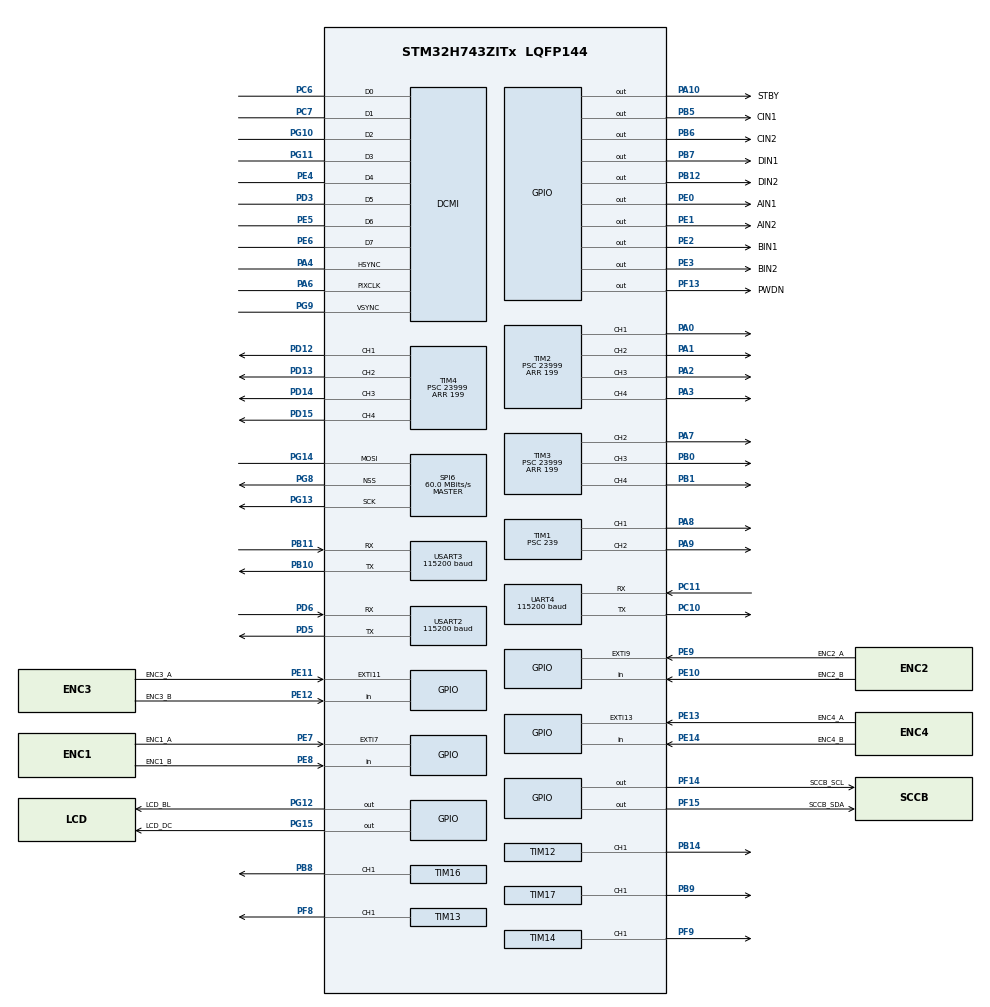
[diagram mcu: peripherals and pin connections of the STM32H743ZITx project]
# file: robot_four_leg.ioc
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CORTEX_M7.AccessPermission-Cortex_Memory_Protection_Unit_Region0_Settings=MPU_REGION_FULL_ACCESS
CORTEX_M7.BaseAddress-Cortex_Memory_Protection_Unit_Region0_Settings=0x30000000
CORTEX_M7.CPU_DCache=Enabled
CORTEX_M7.CPU_ICache=Enabled
CORTEX_M7.Enable-Cortex_Memory_Protection_Unit_Region0_Settings=MPU_REGION_ENABLE
CORTEX_M7.IsBufferable-Cortex_Memory_Protection_Unit_Region0_Settings=MPU_ACCESS_BUFFERABLE
CORTEX_M7.IsCacheable-Cortex_Memory_Protection_Unit_Region0_Settings=MPU_ACCESS_CACHEABLE
CORTEX_M7.IsShareable-Cortex_Memory_Protection_Unit_Region0_Settings=MPU_ACCESS_SHAREABLE
CORTEX_M7.MPU_Control=MPU_PRIVILEGED_DEFAULT
CORTEX_M7.Size-Cortex_Memory_Protection_Unit_Region0_Settings=MPU_REGION_SIZE_512KB
CORTEX_M7.SubRegionDisable-Cortex_Memory_Protection_Unit_Region0_Settings=0x00
CORTEX_M7.default_mode_Activation=0
DCMI.JPEGMode=DCMI_JPEG_DISABLE
DCMI.PCKPolarity=DCMI_PCKPOLARITY_RISING
Dma.DCMI.0.Direction=DMA_PERIPH_TO_MEMORY
Dma.DCMI.0.EventEnable=DISABLE
Dma.DCMI.0.FIFOMode=DMA_FIFOMODE_ENABLE
Dma.DCMI.0.FIFOThreshold=DMA_FIFO_THRESHOLD_HALFFULL
Dma.DCMI.0.Instance=DMA2_Stream7
Dma.DCMI.0.MemBurst=DMA_MBURST_SINGLE
Dma.DCMI.0.MemDataAlignment=DMA_MDATAALIGN_WORD
Dma.DCMI.0.MemInc=DMA_MINC_ENABLE
Dma.DCMI.0.Mode=DMA_CIRCULAR
Dma.DCMI.0.PeriphBurst=DMA_PBURST_SINGLE
Dma.DCMI.0.PeriphDataAlignment=DMA_PDATAALIGN_WORD
Dma.DCMI.0.PeriphInc=DMA_PINC_DISABLE
Dma.DCMI.0.Polarity=HAL_DMAMUX_REQ_GEN_RISING
Dma.DCMI.0.Priority=DMA_PRIORITY_HIGH
Dma.DCMI.0.RequestNumber=1
Dma.DCMI.0.SignalID=NONE
Dma.DCMI.0.SyncEnable=DISABLE
Dma.DCMI.0.SyncPolarity=HAL_DMAMUX_SYNC_NO_EVENT
Dma.DCMI.0.SyncRequestNumber=1
Dma.DCMI.0.SyncSignalID=NONE
Dma.Request0=DCMI
Dma.Request1=USART3_TX
Dma.USART3_TX.1.Direction=DMA_MEMORY_TO_PERIPH
Dma.USART3_TX.1.EventEnable=DISABLE
Dma.USART3_TX.1.FIFOMode=DMA_FIFOMODE_DISABLE
Dma.USART3_TX.1.Instance=DMA1_Stream1
Dma.USART3_TX.1.MemDataAlignment=DMA_MDATAALIGN_BYTE
Dma.USART3_TX.1.MemInc=DMA_MINC_ENABLE
Dma.USART3_TX.1.Mode=DMA_NORMAL
Dma.USART3_TX.1.PeriphDataAlignment=DMA_PDATAALIGN_BYTE
Dma.USART3_TX.1.PeriphInc=DMA_PINC_DISABLE
Dma.USART3_TX.1.Polarity=HAL_DMAMUX_REQ_GEN_RISING
Dma.USART3_TX.1.Priority=DMA_PRIORITY_LOW
Dma.USART3_TX.1.RequestNumber=1
Dma.USART3_TX.1.SignalID=NONE
Dma.USART3_TX.1.SyncEnable=DISABLE
Dma.USART3_TX.1.SyncPolarity=HAL_DMAMUX_SYNC_NO_EVENT
Dma.USART3_TX.1.SyncRequestNumber=1
Dma.USART3_TX.1.SyncSignalID=NONE
IWDG1.Prescaler=IWDG_PRESCALER_32
IWDG1.Reload=2047
Mcu.Family=STM32H7
Mcu.Name=STM32H743ZITx
Mcu.Package=LQFP144
NVIC.DCMI_IRQn=true\:0\:0\:false\:false\:true\:true\:true\:true
NVIC.DMA1_Stream1_IRQn=true\:0\:0\:false\:false\:true\:false\:true\:true
NVIC.DMA2_Stream7_IRQn=true\:0\:0\:false\:false\:true\:false\:true\:true
NVIC.EXTI15_10_IRQn=true\:0\:0\:false\:false\:true\:true\:true\:true
NVIC.EXTI9_5_IRQn=true\:6\:0\:true\:false\:true\:true\:true\:true
NVIC.PriorityGroup=NVIC_PRIORITYGROUP_4
NVIC.TIM6_DAC_IRQn=true\:15\:0\:false\:false\:true\:false\:true\:true
NVIC.TimeBase=TIM6_DAC_IRQn
NVIC.TimeBaseIP=TIM6
NVIC.UART4_IRQn=true\:0\:0\:false\:false\:true\:true\:true\:true
NVIC.USART2_IRQn=true\:5\:0\:true\:false\:true\:true\:true\:true
NVIC.USART3_IRQn=true\:5\:0\:true\:false\:true\:true\:true\:true
PA0.Signal=S_TIM2_CH1_ETR
PA1.Signal=S_TIM2_CH2
PA10.GPIO_Label=STBY
PA10.Signal=GPIO_Output
PA2.Signal=S_TIM2_CH3
PA3.Signal=S_TIM2_CH4
PA4.GPIO_PuPd=GPIO_PULLUP
PA4.GPIO_Speed=GPIO_SPEED_FREQ_VERY_HIGH
PA4.Mode=Slave_8_bits_External_Synchro
PA4.Signal=DCMI_HSYNC
PA6.GPIO_PuPd=GPIO_PULLUP
PA6.GPIO_Speed=GPIO_SPEED_FREQ_VERY_HIGH
PA6.Mode=Slave_8_bits_External_Synchro
PA6.Signal=DCMI_PIXCLK
PA7.Signal=S_TIM3_CH2
PA8.Signal=S_TIM1_CH1
PA9.Signal=S_TIM1_CH2
PB0.Signal=S_TIM3_CH3
PB1.Signal=S_TIM3_CH4
PB10.Mode=Asynchronous
PB10.Signal=USART3_TX
PB11.Mode=Asynchronous
PB11.Signal=USART3_RX
PB12.GPIO_Label=DIN2
PB12.Signal=GPIO_Output
PB14.Signal=S_TIM12_CH1
PB5.GPIO_Label=CIN1
PB5.Signal=GPIO_Output
PB6.GPIO_Label=CIN2
PB6.Signal=GPIO_Output
PB7.GPIO_Label=DIN1
PB7.Signal=GPIO_Output
PB8.Signal=S_TIM16_CH1
PB9.Signal=S_TIM17_CH1
PC10.Mode=Asynchronous
PC10.Signal=UART4_TX
PC11.Mode=Asynchronous
PC11.Signal=UART4_RX
PC14-OSC32_IN\ (OSC32_IN).Mode=LSE-External-Oscillator
PC14-OSC32_IN\ (OSC32_IN).Signal=RCC_OSC32_IN
PC15-OSC32_OUT\ (OSC32_OUT).Mode=LSE-External-Oscillator
PC15-OSC32_OUT\ (OSC32_OUT).Signal=RCC_OSC32_OUT
PC6.GPIO_PuPd=GPIO_PULLUP
PC6.GPIO_Speed=GPIO_SPEED_FREQ_VERY_HIGH
PC6.Mode=Slave_8_bits_External_Synchro
PC6.Signal=DCMI_D0
PC7.GPIO_PuPd=GPIO_PULLUP
PC7.GPIO_Speed=GPIO_SPEED_FREQ_VERY_HIGH
PC7.Mode=Slave_8_bits_External_Synchro
PC7.Signal=DCMI_D1
PD12.Signal=S_TIM4_CH1
PD13.Signal=S_TIM4_CH2
PD14.Signal=S_TIM4_CH3
PD15.Signal=S_TIM4_CH4
PD3.GPIO_PuPd=GPIO_PULLUP
PD3.GPIO_Speed=GPIO_SPEED_FREQ_VERY_HIGH
PD3.Mode=Slave_8_bits_External_Synchro
PD3.Signal=DCMI_D5
PD5.Mode=Asynchronous
PD5.Signal=USART2_TX
PD6.Mode=Asynchronous
PD6.Signal=USART2_RX
PE0.GPIO_Label=AIN1
PE0.Signal=GPIO_Output
PE1.GPIO_Label=AIN2
PE1.Signal=GPIO_Output
PE10.GPIO_Label=ENC2_B
PE10.GPIO_PuPd=GPIO_PULLUP
PE10.Signal=GPIO_Input
PE11.GPIO_Label=ENC3_A
PE11.GPIO_ModeDefaultEXTI=GPIO_MODE_IT_RISING_FALLING
PE11.GPIO_PuPd=GPIO_PULLUP
PE11.Signal=GPXTI11
PE12.GPIO_Label=ENC3_B
PE12.GPIO_PuPd=GPIO_PULLUP
PE12.Signal=GPIO_Input
PE13.GPIO_Label=ENC4_A
PE13.GPIO_ModeDefaultEXTI=GPIO_MODE_IT_RISING_FALLING
PE13.GPIO_PuPd=GPIO_PULLUP
PE13.Signal=GPXTI13
PE14.GPIO_Label=ENC4_B
PE14.GPIO_PuPd=GPIO_PULLUP
PE14.Signal=GPIO_Input
PE2.GPIO_Label=BIN1
PE2.Signal=GPIO_Output
PE3.GPIO_Label=BIN2
PE3.Signal=GPIO_Output
PE4.GPIO_PuPd=GPIO_PULLUP
PE4.GPIO_Speed=GPIO_SPEED_FREQ_VERY_HIGH
PE4.Mode=Slave_8_bits_External_Synchro
PE4.Signal=DCMI_D4
PE5.GPIO_PuPd=GPIO_PULLUP
PE5.GPIO_Speed=GPIO_SPEED_FREQ_VERY_HIGH
PE5.Mode=Slave_8_bits_External_Synchro
PE5.Signal=DCMI_D6
PE6.GPIO_PuPd=GPIO_PULLUP
PE6.GPIO_Speed=GPIO_SPEED_FREQ_VERY_HIGH
PE6.Mode=Slave_8_bits_External_Synchro
PE6.Signal=DCMI_D7
PE7.GPIO_Label=ENC1_A
PE7.GPIO_ModeDefaultEXTI=GPIO_MODE_IT_RISING_FALLING
PE7.GPIO_PuPd=GPIO_PULLUP
PE7.Signal=GPXTI7
PE8.GPIO_Label=ENC1_B
PE8.GPIO_PuPd=GPIO_PULLUP
PE8.Signal=GPIO_Input
PE9.GPIO_Label=ENC2_A
PE9.GPIO_ModeDefaultEXTI=GPIO_MODE_IT_RISING_FALLING
PE9.GPIO_PuPd=GPIO_PULLUP
PE9.Signal=GPXTI9
PF13.GPIO_Label=PWDN
PF13.GPIO_PuPd=GPIO_PULLUP
PF13.Signal=GPIO_Output
PF14.GPIO_Label=SCCB_SCL
PF14.GPIO_ModeDefaultOutputPP=GPIO_MODE_OUTPUT_OD
PF14.GPIO_PuPd=GPIO_NOPULL
PF14.PinState=GPIO_PIN_SET
PF14.Signal=GPIO_Output
PF15.GPIO_Label=SCCB_SDA
PF15.GPIO_ModeDefaultOutputPP=GPIO_MODE_OUTPUT_OD
PF15.GPIO_PuPd=GPIO_NOPULL
PF15.PinState=GPIO_PIN_SET
PF15.Signal=GPIO_Output
PF8.Signal=S_TIM13_CH1
PF9.Signal=S_TIM14_CH1
PG10.GPIO_PuPd=GPIO_PULLUP
PG10.Mode=Slave_8_bits_External_Synchro
PG10.Signal=DCMI_D2
PG11.GPIO_PuPd=GPIO_PULLUP
PG11.Mode=Slave_8_bits_External_Synchro
PG11.Signal=DCMI_D3
PG12.GPIO_Label=LCD_BL
PG12.Signal=GPIO_Output
PG13.GPIO_Speed=GPIO_SPEED_FREQ_VERY_HIGH
PG13.Mode=Simplex_Bidirectional_Master
PG13.Signal=SPI6_SCK
PG14.GPIO_Speed=GPIO_SPEED_FREQ_VERY_HIGH
PG14.Mode=Simplex_Bidirectional_Master
PG14.Signal=SPI6_MOSI
PG15.GPIO_Label=LCD_DC
PG15.Signal=GPIO_Output
PG8.GPIO_Speed=GPIO_SPEED_FREQ_VERY_HIGH
PG8.Mode=NSS_Signal_Hard_Output
PG8.Signal=SPI6_NSS
PG9.GPIO_PuPd=GPIO_PULLUP
PG9.GPIO_Speed=GPIO_SPEED_FREQ_VERY_HIGH
PG9.Mode=Slave_8_bits_External_Synchro
PG9.Signal=DCMI_VSYNC
PH0-OSC_IN\ (PH0).Mode=HSE-External-Oscillator
PH0-OSC_IN\ (PH0).Signal=RCC_OSC_IN
PH1-OSC_OUT\ (PH1).Mode=HSE-External-Oscillator
PH1-OSC_OUT\ (PH1).Signal=RCC_OSC_OUT
ProjectManager.HeapSize=0x200
ProjectManager.StackSize=0x400
ProjectManager.TargetToolchain=STM32CubeIDE
RCC.ADCFreq_Value=129000000
RCC.APB1Freq_Value=120000000
RCC.APB2Freq_Value=120000000
RCC.APB3Freq_Value=120000000
RCC.APB4Freq_Value=120000000
RCC.CortexFreq_Value=480000000
RCC.D1PPRE=RCC_APB3_DIV2
RCC.D2PPRE1=RCC_APB1_DIV2
RCC.D2PPRE2=RCC_APB2_DIV2
RCC.D3PPRE=RCC_APB4_DIV2
RCC.DIVM1=4
RCC.DIVN1=60
RCC.HCLKFreq_Value=240000000
RCC.HPRE=RCC_HCLK_DIV2
RCC.PLL2FRACN=0
RCC.PLL3FRACN=0
RCC.PLLFRACN=0
RCC.SYSCLKFreq_VALUE=480000000
RCC.SYSCLKSource=RCC_SYSCLKSOURCE_PLLCLK
RCC.USBFreq_Value=480000000
SH.S_TIM12_CH1.0=TIM12_CH1,PWM Generation1 CH1
SH.S_TIM13_CH1.0=TIM13_CH1,PWM Generation1 CH1
SH.S_TIM14_CH1.0=TIM14_CH1,PWM Generation1 CH1
SH.S_TIM16_CH1.0=TIM16_CH1,PWM Generation1 CH1
SH.S_TIM17_CH1.0=TIM17_CH1,PWM Generation1 CH1
SH.S_TIM1_CH1.0=TIM1_CH1,PWM Generation1 CH1
SH.S_TIM1_CH2.0=TIM1_CH2,PWM Generation2 CH2
SH.S_TIM2_CH1_ETR.0=TIM2_CH1,PWM Generation1 CH1
SH.S_TIM2_CH2.0=TIM2_CH2,PWM Generation2 CH2
SH.S_TIM2_CH3.0=TIM2_CH3,PWM Generation3 CH3
SH.S_TIM2_CH4.0=TIM2_CH4,PWM Generation4 CH4
SH.S_TIM3_CH2.0=TIM3_CH2,PWM Generation2 CH2
SH.S_TIM3_CH3.0=TIM3_CH3,PWM Generation3 CH3
SH.S_TIM3_CH4.0=TIM3_CH4,PWM Generation4 CH4
SH.S_TIM4_CH1.0=TIM4_CH1,PWM Generation1 CH1
SH.S_TIM4_CH2.0=TIM4_CH2,PWM Generation2 CH2
SH.S_TIM4_CH3.0=TIM4_CH3,PWM Generation3 CH3
SH.S_TIM4_CH4.0=TIM4_CH4,PWM Generation4 CH4
SPI6.CalculateBaudRate=60.0 MBits/s
SPI6.DataSize=SPI_DATASIZE_8BIT
SPI6.Direction=SPI_DIRECTION_1LINE
SPI6.FifoThreshold=SPI_FIFO_THRESHOLD_02DATA
SPI6.Mode=SPI_MODE_MASTER
SPI6.VirtualNSS=VM_NSSHARD
SPI6.VirtualType=VM_MASTER
TIM1.Channel-PWM\ Generation1\ CH1=TIM_CHANNEL_1
TIM1.Channel-PWM\ Generation2\ CH2=TIM_CHANNEL_2
TIM1.Period=99
TIM1.Prescaler=239
TIM12.AutoReloadPreload=TIM_AUTORELOAD_PRELOAD_ENABLE
TIM12.Channel-PWM\ Generation1\ CH1=TIM_CHANNEL_1
TIM12.Period=199
TIM12.Prescaler=23999
TIM13.AutoReloadPreload=TIM_AUTORELOAD_PRELOAD_ENABLE
TIM13.Channel=TIM_CHANNEL_1
TIM13.Period=199
TIM13.Prescaler=23999
TIM14.AutoReloadPreload=TIM_AUTORELOAD_PRELOAD_ENABLE
TIM14.Channel=TIM_CHANNEL_1
TIM14.Period=199
TIM14.Prescaler=23999
TIM16.Channel=TIM_CHANNEL_1
TIM16.Period=99
TIM16.Prescaler=239
TIM17.Channel=TIM_CHANNEL_1
TIM17.Period=99
TIM17.Prescaler=239
TIM2.AutoReloadPreload=TIM_AUTORELOAD_PRELOAD_ENABLE
TIM2.Channel-PWM\ Generation1\ CH1=TIM_CHANNEL_1
TIM2.Channel-PWM\ Generation2\ CH2=TIM_CHANNEL_2
TIM2.Channel-PWM\ Generation3\ CH3=TIM_CHANNEL_3
TIM2.Channel-PWM\ Generation4\ CH4=TIM_CHANNEL_4
TIM2.Period=199
TIM2.Prescaler=23999
TIM3.AutoReloadPreload=TIM_AUTORELOAD_PRELOAD_ENABLE
TIM3.Channel-PWM\ Generation2\ CH2=TIM_CHANNEL_2
TIM3.Channel-PWM\ Generation3\ CH3=TIM_CHANNEL_3
TIM3.Channel-PWM\ Generation4\ CH4=TIM_CHANNEL_4
TIM3.Period=199
TIM3.Prescaler=23999
TIM4.AutoReloadPreload=TIM_AUTORELOAD_PRELOAD_ENABLE
TIM4.Channel-PWM\ Generation1\ CH1=TIM_CHANNEL_1
TIM4.Channel-PWM\ Generation2\ CH2=TIM_CHANNEL_2
TIM4.Channel-PWM\ Generation3\ CH3=TIM_CHANNEL_3
TIM4.Channel-PWM\ Generation4\ CH4=TIM_CHANNEL_4
TIM4.Period=199
TIM4.Prescaler=23999
UART4.BaudRate=115200
USART2.BaudRate=115200
USART2.VirtualMode-Asynchronous=VM_ASYNC
USART3.BaudRate=115200
USART3.VirtualMode-Asynchronous=VM_ASYNC
VP_IWDG1_VS_IWDG.Mode=IWDG_Activate
VP_MEMORYMAP_VS_MEMORYMAP.Mode=CurAppReg
VP_SYS_VS_tim6.Mode=TIM6
VP_TIM12_VS_ClockSourceINT.Mode=Internal
VP_TIM13_VS_ClockSourceINT.Mode=Enable_Timer
VP_TIM14_VS_ClockSourceINT.Mode=Enable_Timer
VP_TIM16_VS_ClockSourceINT.Mode=Enable_Timer
VP_TIM17_VS_ClockSourceINT.Mode=Enable_Timer
VP_TIM1_VS_ClockSourceINT.Mode=Internal
VP_TIM5_VS_ClockSourceINT.Mode=Internal
board=custom

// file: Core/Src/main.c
/* USER CODE BEGIN Header */
/**
  ******************************************************************************
  * @file           : main.c
  * @brief          : Main program body
  ******************************************************************************
  * @attention
  *
  * Copyright (c) 2026 STMicroelectronics.
  * All rights reserved.
  *
  * This software is licensed under terms that can be found in the LICENSE file
  * in the root directory of this software component.
  * If no LICENSE file comes with this software, it is provided AS-IS.
  *
  ******************************************************************************
  */
/* USER CODE END Header */
#include "main.h"
#include "dcmi.h"
#include "dma.h"
#include "iwdg.h"
#include "spi.h"
#include "tim.h"
#include "usart.h"
#include "gpio.h"

/* USER CODE BEGIN Includes */
#include "motor_control.h"
#include "new_servo.h"
#include "leg_control.h"
#include "encoder.h"
#include "bluetooth_control.h"
#include "imu.h"
#include "leg_ik.h"
#include "walk_gait.h"
#include "attitude_control.h"
#include "drive_ctrl.h"
#include "gimbal.h"
#include <stdio.h>
#include <math.h>
/* USER CODE END Includes */

/* USER CODE BEGIN PTD */
/* 控制模式: 上电默认校准模式(不动), 蓝牙命令切换 */
typedef enum { MODE_CALIB = 0, MODE_STAND, MODE_TROT, MODE_STEP } ctrl_mode_t;

#define CROUCH_X_F   30.0f    /* 正常分支低趴: 前腿足端前伸 (膝轴离地86mm) */
#define CROUCH_X_FR 114.5f    /* 反折分支低趴: 前足+129.5, 大腿≈水平(q2=85)+小腿垂直(q3=-85) */
#define CROUCH_X_R  144.5f    /* 正常分支低趴后伸: 后足15-144.5=-129.5, 与前足对称 (L 视觉姿态) */
#define CROUCH_X_RR 135.0f    /* 反折分支低趴后伸 (支撑中心在身下, 前后对称) */

#define FLIP_H         240.0f /* 翻膝机动高度: 此高度下前膝全程≥110mm */
#define FLIP_SEG_MS    900u   /* 翻膝单段时长 (伸/收各900ms) */
#define FLIP_SETTLE_MS 800u   /* 到位后等待平滑收敛再翻膝 */

#define PARK_H          72.0f /* 收纳姿态站高: 贴地趴 (肚皮离地~32mm, 断电无砸落) */
#define PARK_X_F       282.0f /* 贴地趴前足前伸量 (15+282=297, 腿伸直) */
#define PARK_X_R       312.0f /* 贴地趴后足后伸量 (15-312=-297) */

#define RISE_CM_X       15.0f /* 站起阶段重心后移量: 足端前移=身体后坐, 卸载前腿 */
#define RISE_CM_Y       10.0f /* 站起阶段重心左移量: 卸载右腿(FR堵转), 载荷给强壮的RL */

#define SIT_Z_F        310.0f /* 坐姿前腿足端z: 腿竖直伸直 (q2≈q3≈0, 直腿点) */
#define SIT_Z_R        240.0f /* 坐姿后腿足端z: 反折深蹲 */
#define SIT_X_R         95.0f /* 坐姿后足后伸量 (15-95=-80, 膝后折72°) */

/* 前后腿膝分支: 0=正常(狗姿态) 1=反折(膝盖往前顶) */
static uint8_t  g_front_rev = 0;
static uint8_t  g_rear_rev  = 0;
static uint8_t  g_park      = 0;   /* 收纳姿态 (C 命令): 72mm 贴地趴 */
static uint8_t  g_sit       = 0;   /* 坐姿 (O 命令): 前腿竖直伸直 + 后腿反折深蹲 */
static uint8_t  g_rise      = 0;   /* 规划式站起 (U 命令): 1=阶段A收腿+顶升 */
static uint32_t g_rise_t0   = 0;
static float    g_rise_h0   = 0;   /* 站起阶段A起始高度 */
static uint8_t  g_booted    = 1;   /* 刚上电标志: U 站起在上电后可用 (假定在趴姿) */

/* 控制模式与行走时刻 (PTD 函数也要用, 声明放这里) */
static ctrl_mode_t g_mode    = MODE_CALIB;
static uint32_t    g_walk_t0 = 0; /* 行走起始时刻 (相位基准) */

/* 横移走状态: F 命令开启 (0=前后trot, 1=横向螃蟹步), g_lat_dir 为方向 */
static uint8_t  g_gait_lat = 0;
static int      g_lat_dir  = 1;

/* 自稳标定: Z 命令采样中标志 (完成时发 CAL:OK) */
static uint8_t  g_calib_pending = 0;

/* 站立自稳: L:1/L:0 开关, 10Hz 更新四腿z补偿 (仅H/K高站姿, Z标定后可用) */
static float    g_lv_dz[4] = {0, 0, 0, 0};
static uint32_t g_lv_last  = 0;
static uint8_t  g_lv_act   = 0;   /* 自稳激活状态 (10Hz块更新, 行走循环消费) */

/* W原地抬腿重心左移补偿 (mm): 机身右侧偏重 → 右倾+右转, 足端右移=身体左移
 * W:毫米 命令在线调 (默认15) */
static float    g_w_com = 15.0f;

/* 按键页速度档 (D 命令缺省速度, U:1/U:0 加减, 步进5, 范围10~50) */
static int8_t   g_btn_spd     = 30;
static uint8_t  g_btn_dir     = 0;    /* 最后按键方向 */
static uint8_t  g_btn_mode    = 0;    /* 最后按键模式 0=经典 1=无倾斜页 */
static uint8_t  g_btn_driving = 0;    /* 当前是否按键驾驶中 (V摇杆接管时清) */

/* 站姿宽度偏移 (Y:毫米 命令, ±40, 默认0): 每足足端向外偏移, 支撑面加宽
 * 崎岖地面抗侧倾测试用; 同时用于实测验证外展y通道方向 */
static float    g_stance_w = 0.0f;

/* 单腿抬腿 (N:腿:动作): 任意时刻只操作一条腿
 * 抬起 50mm + 前伸 80mm (实测确认), 放下后足端停在前伸位, 姿态命令收回 */
#define LEGLIFT_H      50.0f   /* 抬腿高度 mm */
#define LEGLIFT_FWD    80.0f   /* 前伸量 mm */
#define LEGLIFT_UP_MS  800u    /* 抬起耗时 */
#define LEGLIFT_DN_MS  1200u   /* 放下耗时 (慢慢放) */
#define LEGLIFT_SHIFT  15.0f   /* 支撑腿重心横移 (mm): 远离抬起腿, 重心移进支撑三角形 */
#define LEGLIFT_STAG_MS 0u     /* 双腿模式交错间隔 (2026-08-25 改同时抬: 0=同时) */
static uint8_t  g_lift_leg   = 0xFF; /* 当前抬起的腿 0~3, 0xFF=无 */
static uint8_t  g_lift_phase = 0;    /* 1=抬起中 2=悬空 3=放下中 (0=待命) */
static uint32_t g_lift_t0    = 0;
static float    g_lift_x0    = 0;    /* 抬起起始x (站立位+前伸记忆) */
static float    g_lift_z3    = 0;    /* 放下起始z (抬起中被打断时为当前z) */
static float    g_lift_x3    = 0;    /* 放下起始x */
static float    g_lift_dx    = 0;    /* 本次抬腿的前伸增量 (已达80上限的腿=0, 原地抬) */
static float    g_leg_fwd[4] = {0, 0, 0, 0}; /* 每腿落地后的前伸记忆 (mm), 姿态命令清零 */

/* 抬腿状态是否作用于该腿: 单腿(0~3)精确匹配; 双腿模式 4=前双(0/1) 5=后双(2/3) */
static uint8_t LegLiftActive(uint8_t leg)
{
    if (g_lift_leg == leg) return 1;
    if (g_lift_leg == 4u && leg <= 1u) return 1;
    if (g_lift_leg == 5u && leg >= 2u) return 1;
    return 0;
}

/* 单腿/双腿抬腿缓动系数 (0→1, cos 平滑; 双腿模式第二条腿错开0.3s) */
static float LegLiftEase(uint8_t leg)
{
    uint32_t ms = (g_lift_phase == 1) ? LEGLIFT_UP_MS : LEGLIFT_DN_MS;
    uint32_t t0 = g_lift_t0;
    if (g_lift_leg >= 4u &&
        ((g_lift_leg == 4u && leg == 1u) || (g_lift_leg == 5u && leg == 3u)))
        t0 += LEGLIFT_STAG_MS;
    float u = (float)(uwTick - t0) / (float)ms;
    if (u < 0.0f) u = 0.0f;
    if (u > 1.0f) u = 1.0f;
    return 0.5f - 0.5f * cosf(3.14159265f * u);
}

/* 单腿抬腿足端 x: 抬起中边抬边前伸, 其余相位保持前伸位 (仅单腿模式用) */
static float LegLiftX(void)
{
    float xf = g_lift_x0 + g_lift_dx;
    if (g_lift_phase == 1) return g_lift_x0 + (xf - g_lift_x0) * LegLiftEase(g_lift_leg);
    if (g_lift_phase == 3) return g_lift_x3 + (xf - g_lift_x3) * LegLiftEase(g_lift_leg);
    return xf;
}

/* 单腿抬腿复位 (姿态/行走命令): 状态机 + 前伸记忆全清, 四足滚回站立位 */
static void LegLiftReset(void)
{
    g_lift_leg = 0xFF;
    g_lift_phase = 0;
    for (int i = 0; i < 4; i++) g_leg_fwd[i] = 0.0f;
}

/* 单腿/双腿抬腿足端 z (下向距离): 抬/悬/放 状态机 (双腿直抬, 无前伸) */
static float LegLiftZ(uint8_t leg, float h)
{
    float zu = h - LEGLIFT_H;
    if (g_lift_phase == 1) return h  + (zu - h) * LegLiftEase(leg);
    if (g_lift_phase == 2) return zu;
    if (g_lift_phase == 3) return g_lift_z3 + (h - g_lift_z3) * LegLiftEase(leg);
    return h;
}

/* IMU 上报: I 命令开关, 10Hz 固定频率 */
static uint8_t  g_imu_stream = 0;
static uint32_t g_imu_last   = 0;
static uint8_t  g_imu_diag   = 0;  /* I 按下后主循环发一次诊断 */

/* 编码器转速上报: J 命令开关, 10Hz */
static uint8_t  g_enc_stream = 0;
static uint32_t g_enc_last   = 0;

/* 翻膝机动状态 (姿态切换专用: 指定腿组的足端伸到直腿点再收回, 中点翻转膝分支) */
static uint8_t  g_flip_on    = 0;   /* 翻膝进行中 */
static uint32_t g_flip_t0    = 0;   /* 翻膝起始时刻 */
static uint32_t g_flip_start = 0;   /* 翻膝定时启动 (0=无计划) */
static uint8_t  g_flip_mask  = 0;   /* 翻膝腿组: bit0=前腿 bit1=后腿 */
static float    g_flip_x0f   = 0;   /* 前腿起点/终点x */
static float    g_flip_x0r   = 0;   /* 后腿起点/终点x */
static float    g_flip_xm    = 0;   /* 直腿点x幅度 (两分支在此连续) */
static uint8_t  g_flip_revf  = 0;   /* 翻膝后前腿分支 */
static uint8_t  g_flip_revr  = 0;   /* 翻膝后后腿分支 */
static uint8_t  g_flip_post  = 0;   /* 翻膝完成后: 1=趴LOW 2=升HIGH 3=开W 4=开F 5=趴PARK 7=坐姿 8=降到指定高度 */
static float    g_flip_post_h = 0;   /* post=8 的目标站高 (H:高度命令) */

/* 站起阶段重心挪移系数: h<100 无几何空间(腿近伸直), 100~160 渐变, ≥160 全量 */
static float RiseCmK(void)
{
    float k = (g_walk_params.stand_h - 100.0f) / 60.0f;
    if (k < 0.0f) return 0.0f;
    if (k > 1.0f) return 1.0f;
    return k;
}

/* 站姿足端 x: 前移修正 + 低趴外伸 + 坡度修正 (站高越低, 前后腿越往外伸) */
static float StandFootX(uint8_t leg)
{
    if (g_park) {
        /* 贴地趴: 前腿反折前伸直 x+297 / 后腿正常后伸直 x-297 (膝高~67mm) */
        if (leg < 2)
            return g_walk_params.foot_x_shift + PARK_X_F;
        return g_walk_params.foot_x_shift - PARK_X_R;
    }
    if (g_rise == 1) {
        /* 站起阶段A: 先顶升后收腿 (低力矩路径)
         * 反折前腿/正常后腿在低站高时只能近伸直前伸/后伸 (大腿 q2=±90 限制):
         * 足端收拢量随站高上升逐步放开, 沿 大腿(q2) + 小腿(q3) 双边界内收。
         * 2026-08-21 修复: 原轨迹只限小腿, 低处要求 q2>90 → IK钳位 →
         * 前腿被指令压进地面 (FR 堵转)。 */
        float h = g_walk_params.stand_h;
        /* 大腿 q2=±90 边界: 低处足端必须保持外伸, h≥180 后放开 (前后腿对称)
         * +2mm 安全余量: 目标恰好压在边界上时 IK 数值会微超 ±90 被钳 */
        float xq2 = (h < 180.0f) ? (130.0f + sqrtf(32400.0f - h * h) + 2.0f) : 0.0f;
        float bf = sqrtf(53361.0f - h * h);   /* FL小腿边界 (q3=-85) */
        if (bf < 0.0f) bf = 0.0f;
        float xf = 15.0f + CROUCH_X_FR;       /* =129.5, 前顶低趴前足 (h≤191恒k=1) */
        if (bf > xf)  xf = bf;
        if (xq2 > xf) xf = xq2;
        float br = sqrtf(43594.0f - h * h);   /* RL小腿边界 (q3=+97) */
        if (br < 0.0f) br = 0.0f;
        float xr = CROUCH_X_R - 15.0f;        /* =129.5, 前顶低趴后足幅度 (终点对齐L) */
        if (br > xr)  xr = br;
        if (xq2 > xr) xr = xq2;
        /* 重心后移: 足端整体前移 = 身体后坐, 卸载前腿 (FR 堵转补偿) */
        float cmx = RISE_CM_X * RiseCmK();
        if (leg < 2)
            return g_walk_params.foot_x_shift + xf + cmx;
        return g_walk_params.foot_x_shift - xr + cmx;
    }
    if (g_sit) {
        /* 坐姿: 前腿竖直伸直(x=0, z=310) + 后腿反折深蹲(x=-80, z=240) */
        if (leg < 2)
            return g_walk_params.foot_x_shift - 15.0f;
        return g_walk_params.foot_x_shift - SIT_X_R;
    }
    float k = (STAND_H_HIGH - g_walk_params.stand_h) / (STAND_H_HIGH - STAND_H_LOW);
    if (k < 0.0f) k = 0.0f;
    if (k > 1.0f) k = 1.0f;
    if (leg < 2)
        return g_walk_params.foot_x_shift +
               (g_front_rev ? CROUCH_X_FR * k : CROUCH_X_F * k);
    return g_walk_params.foot_x_shift -
           (g_rear_rev ? CROUCH_X_RR * k : CROUCH_X_R * k);
}

/* 直腿点x: 足端在高度h下伸到腿完全伸直的位置 (两分支在此连续) */
static float FlipStraightX(float h)
{
    float dmax = (LEG_L1 + LEG_L2) * 0.9999f;
    float d2 = dmax * dmax - h * h;
    return (d2 > 0.0f) ? sqrtf(d2) : 0.0f;
}

/* 开始翻膝机动 (前腿往+伸, 后腿往-伸) */
static void FlipBegin(void)
{
    g_flip_x0f = StandFootX(0) + g_walk_params.foot_x_corr[0];
    g_flip_x0r = StandFootX(2) + g_walk_params.foot_x_corr[2];
    g_flip_xm  = FlipStraightX(g_walk_params.stand_h);
    g_flip_t0  = uwTick;
    g_flip_on  = 1;
    bluetooth_send("FLIP\r\n");
}

/* 启动 trot: 恢复行走参数 + 停电机 + 相位归零, 可选重心横移模式
 * wheel_pct: 轮助走占空比 (T 前进行走=10%, E 转圈=0); back: 1=倒着走(负步幅+轮反向) */
static void TrotStart(uint8_t shift_mode, uint8_t wheel_pct, uint8_t back, const char *reply)
{
    g_flip_on = 0; g_flip_start = 0;
    g_walk_params.step_len = back ? -60.0f : 60.0f;   /* 负步幅=倒走 (支撑相反向推) */
    g_walk_params.step_h   = 25.0f;
    DriveCtrl_Reset();           /* 接管电机前先复位摇杆驱动 */
    g_booted = 0;
    g_sit = 0;
    g_shift_mode = shift_mode;
    g_gait_lat = 0;              /* 前后 trot */
    g_walk_t0 = uwTick;          /* 相位从零开始 */
    g_mode = MODE_TROT;
    for (int i = 0; i < 4; i++) {
        if (wheel_pct > 0)
            Motor_Set((uint8_t)i, wheel_pct, back ? 0 : 1);
        else
            Motor_Stop((uint8_t)i);
    }
    bluetooth_send(reply);
}
/* USER CODE END PTD */

/* USER CODE BEGIN PD */
#define CTRL_PERIOD_MS  5u    /* 控制节拍 5ms = 200Hz */
/* USER CODE END PD */

/* USER CODE BEGIN PV */
uint8_t bt_rx_byte;           /* 蓝牙接收字节 */
uint8_t imu_rx_byte;          /* IMU 接收字节 */
static float       g_cmd_deg[12];   /* 当前舵机指令角 (平滑用) */
static uint32_t    g_ctrl_last = 0; /* 控制节拍计时 */
static float       g_step_t    = 0; /* 单步调试: 冻结的行走时刻 */
static int         g_step_cnt  = 0; /* 单步计数 0~3 -> PH:0/90/180/270 */
static uint8_t     g_rise_slow    = 0;             /* 站高上升标记: 低趴升站用慢速平滑 */
static float       g_stand_h_prev = STAND_H_HIGH; /* 上一目标站高 (判升/降方向) */
static ctrl_mode_t g_mode_prev    = MODE_CALIB;   /* 上一拍模式 (退出行走时停轮用) */
/* USER CODE END PV */

void SystemClock_Config(void);
static void MPU_Config(void);

/* USER CODE BEGIN 0 */

// 弱实现：无调试器时防止printf调用空指针引发HardFault；调试器连接时semihosting覆盖此实现
__attribute__((weak)) int __io_putchar(int ch)
{
  (void)ch;
  return ch;
}

/* USER CODE END 0 */

int main(void)
{

  /* MPU Configuration--------------------------------------------------------*/
  MPU_Config();

  /* Enable the CPU Cache */

  /* Enable I-Cache---------------------------------------------------------*/
  SCB_EnableICache();

  /* Enable D-Cache---------------------------------------------------------*/
  SCB_EnableDCache();

  /* MCU Configuration--------------------------------------------------------*/

  /* Reset of all peripherals, Initializes the Flash interface and the Systick. */
  HAL_Init();

  /* Configure the system clock */
  SystemClock_Config();

  /* Initialize all configured peripherals */
  MX_GPIO_Init();
  MX_DMA_Init();
  MX_SPI6_Init();
  MX_DCMI_Init();
  MX_TIM2_Init();
  MX_TIM3_Init();
  MX_TIM4_Init();
  MX_TIM12_Init();
  MX_TIM1_Init();
  MX_TIM16_Init();
  MX_TIM17_Init();
  MX_TIM5_Init();
  MX_USART3_UART_Init();
  MX_USART2_UART_Init();
  MX_UART4_Init();
  MX_TIM13_Init();
  MX_TIM14_Init();
  MX_IWDG1_Init();
  /* USER CODE BEGIN 2 */

  /* ====== 舵机校准：先强制拉低引脚，再开 PWM ====== */
  HAL_GPIO_WritePin(GPIOA, GPIO_PIN_0|GPIO_PIN_1|GPIO_PIN_2|GPIO_PIN_3|GPIO_PIN_7, GPIO_PIN_RESET);
  HAL_GPIO_WritePin(GPIOB, GPIO_PIN_0|GPIO_PIN_1|GPIO_PIN_14, GPIO_PIN_RESET);
  HAL_GPIO_WritePin(GPIOD, GPIO_PIN_12|GPIO_PIN_13|GPIO_PIN_14|GPIO_PIN_15, GPIO_PIN_RESET);
  NewServo_StartAll();

  Motor_Init();   /* 电机 PWM 启动, CCR=0 不转, STBY 拉高待命 */

  Gimbal_Init();  /* 云台舵机 (TIM8 CH3/CH4), 默认居中 135/135 */

  /* 外展 4 舵机错开 100ms 上电锁定站姿角, 防乱动 */
  for (int leg = 0; leg < 4; leg++) {
      Leg_SetJoint((uint8_t)leg, JOINT_ABD, STAND_POSE[leg][JOINT_ABD]);
      HAL_Delay(100);
  }

  /* 指令角初始化: 外展=锁定值, 大腿/小腿=IK站姿解 (首次G写入即站姿, 不跳变) */
  LegIK_SetFrontReversed(0);   /* 上电默认狗姿态 (前后腿正常膝分支) */
  LegIK_SetRearReversed(0);
  for (int leg = 0; leg < 4; leg++) {
      float d_leg = (leg == 0 || leg == 2) ? -LEG_HIP_D : LEG_HIP_D;
      uint16_t deg[3];
      LegIK_SolveServo((uint8_t)leg, StandFootX((uint8_t)leg), d_leg, g_walk_params.stand_h, deg);
      g_cmd_deg[leg]     = (float)STAND_POSE[leg][JOINT_ABD];
      g_cmd_deg[leg + 4] = (float)deg[1];   /* 大腿 */
      g_cmd_deg[leg + 8] = (float)deg[2];   /* 小腿 */
  }

  HAL_UART_Receive_IT(&huart2, &imu_rx_byte, 1);   /* IMU 数据流 (PD6, 115200bps) */
  HAL_UART_Receive_IT(&huart3, &bt_rx_byte, 1);
  Encoder_Init();   /* 编码器计数清零 */
  bluetooth_send("READY\r\n");   /* 上电自检: TX/DMA 通不通 */

  /* 环回自测: PD5(TX) 发 5 字节, 短接 PD5-PD6 后 raw 应 >=5 */
  {
      static const uint8_t loop_test[] = {0x55, 0x51, 0x00, 0x00, 0xA6};
      HAL_UART_Transmit(&huart2, (uint8_t *)loop_test, 5, 100);
  }
  /* USER CODE END 2 */

  /* Infinite loop */
  while (1)
  {

    /* USER CODE BEGIN 3 */

    HAL_IWDG_Refresh(&hiwdg1);   /* 喂狗: 主循环死掉/Error_Handler 超2秒 → 自动复位, 蓝牙失效免断电 */

    /* ====== 编码器转速上报: J 命令开启后 10Hz, 帧尾 520 ====== */
    if (g_enc_stream && (uint32_t)(uwTick - g_enc_last) >= 100u) {
        g_enc_last = uwTick;
        static char ebuf[40];
        snprintf(ebuf, sizeof(ebuf), "E,%d,%d,%d,%d,520\r\n",
                 (int)DriveCtrl_GetRPM(0), (int)DriveCtrl_GetRPM(1),
                 (int)DriveCtrl_GetRPM(2), (int)DriveCtrl_GetRPM(3));
        bluetooth_send(ebuf);
    }

    /* ====== IMU 姿态上报: I 命令开启后 10Hz, 帧尾 520 (参考 adc_10 风格) ====== */
    if (g_imu_stream && (uint32_t)(uwTick - g_imu_last) >= 100u) {
        g_imu_last = uwTick;
        const IMU_Angle *a = IMU_GetAngle();
        /* 定点×10 (0.1°分辨率), 全整数传输, 避免浮点打印 */
        int16_t rx = (int16_t)(a->roll  * 10.0f + (a->roll  >= 0 ? 0.5f : -0.5f));
        int16_t px = (int16_t)(a->pitch * 10.0f + (a->pitch >= 0 ? 0.5f : -0.5f));
        int16_t yx = (int16_t)(a->yaw   * 10.0f + (a->yaw   >= 0 ? 0.5f : -0.5f));
        static char ibuf[40];   /* static: DMA 发送期间缓冲区必须有效 */
        snprintf(ibuf, sizeof(ibuf), "R,%d,P,%d,Y,%d,520\r\n", (int)rx, (int)px, (int)yx);
        bluetooth_send(ibuf);
    }

    /* ====== USART2 接收链看门狗: 每1s检查, 断链自动重装 (双保险) ====== */
    {
        static uint32_t rx_wd_last = 0;
        if ((uint32_t)(uwTick - rx_wd_last) >= 1000u) {
            rx_wd_last = uwTick;
            if (huart2.RxState != HAL_UART_STATE_BUSY_RX) {
                huart2.RxState = HAL_UART_STATE_READY;
                HAL_UART_Receive_IT(&huart2, &imu_rx_byte, 1);
            }
        }
    }

    /* ====== IMU 诊断: 按 I 后报告 USART2 寄存器与收发计数 (主循环发, 避开ISR DMA死锁) ====== */
    if (g_imu_diag) {
        g_imu_diag = 0;
        static char dbg[128];
        snprintf(dbg, sizeof(dbg),
            "DBG2:CR1=%08lX ISR=%08lX MODER=%08lX AFR=%08lX gSt=%d RxSt=%d raw=%lu frames=%lu\r\n",
            (unsigned long)USART2->CR1,
            (unsigned long)USART2->ISR,
            (unsigned long)GPIOD->MODER,
            (unsigned long)GPIOD->AFR[0],
            (int)huart2.gState, (int)huart2.RxState,
            (unsigned long)IMU_GetRawCount(),
            (unsigned long)IMU_GetFrameCount());
        bluetooth_send(dbg);
    }

    /* ====== IMU 诊断: I 开启但 5s 无有效帧 → 报告收发计数 ====== */
    if (g_imu_stream && IMU_Timeout(5000)) {
        static uint32_t diag_last = 0;
        if ((uint32_t)(uwTick - diag_last) >= 2000u) {  /* 每2s一条, 不刷屏 */
            diag_last = uwTick;
            static char dbuf[64];
            snprintf(dbuf, sizeof(dbuf),
                     "IMU:NO DATA raw=%lu frames=%lu\r\n",
                     (unsigned long)IMU_GetRawCount(),
                     (unsigned long)IMU_GetFrameCount());
            bluetooth_send(dbuf);
        }
    }

    /* ====== 5ms 控制节拍: IK解算 + 指数平滑 + 批量输出 ====== */
    if ((uint32_t)(uwTick - g_ctrl_last) >= CTRL_PERIOD_MS) {
        g_ctrl_last = uwTick;

        /* 翻膝定时启动 (命令设的延迟到点后开始) */
        if (g_flip_start && (int32_t)(uwTick - g_flip_start) >= 0) {
            g_flip_start = 0;
            FlipBegin();
        }

        /* 单腿抬腿状态机: 相位推进 + 模式失配自动清除 */
        if (g_lift_leg != 0xFF) {
            if (!(g_mode == MODE_STAND && !g_park && !g_rise &&
                  !g_flip_on && !g_sit)) {
                LegLiftReset();         /* 行走/翻膝/收纳/站起/坐姿: 自动收回 */
            } else if (g_lift_phase == 1 &&
                       (uint32_t)(uwTick - g_lift_t0) >=
                       LEGLIFT_UP_MS + ((g_lift_leg >= 4u) ? LEGLIFT_STAG_MS : 0u)) {
                g_lift_phase = 2;       /* 抬起完成: 悬空 (双腿含交错) */
            } else if (g_lift_phase == 3 &&
                       (uint32_t)(uwTick - g_lift_t0) >=
                       LEGLIFT_DN_MS + ((g_lift_leg >= 4u) ? LEGLIFT_STAG_MS : 0u)) {
                /* 放下完成: 单腿前伸记忆生效; 释放状态机 (其它腿立即可抬) */
                if (g_lift_leg < 4u)
                    g_leg_fwd[g_lift_leg] += g_lift_dx;
                g_lift_leg = 0xFF;
                g_lift_phase = 0;
            }
        }

        /* 摇杆驱动: 占空比斜坡 + 电机差速 + 倾斜状态机 (每5ms) */
        DriveCtrl_Update();

        /* 退出行走模式→站立时停轮 (T 轮助走10% 随行走结束停止; 急停用 S) */
        if (g_mode == MODE_STAND && g_mode_prev == MODE_TROT) {
            for (int i = 0; i < 4; i++)
                Motor_Stop((uint8_t)i);
        }
        g_mode_prev = g_mode;

        /* 规划式站起: 单段顶升+收腿 → 前顶低趴 191 (3.5s 缓升)
         * 2026-08-21 改: 趴姿(前反折+后正常)与前顶低趴同膝分支,
         * 免翻膝、免回高站姿, 直接站到 L 视觉姿态 (之后 G/K 可再升) */
        if (g_rise == 1) {
            float t = (float)(uwTick - g_rise_t0) / 1000.0f;
            float h = g_rise_h0 + (STAND_H_L_FRONT - g_rise_h0) * (t / 3.5f);
            if (h > STAND_H_L_FRONT) h = STAND_H_L_FRONT;
            g_walk_params.stand_h = h;
            if (t >= 3.5f) {
                g_rise = 0;
                bluetooth_send("LOW\r\n");   /* 站起完成: 前顶低趴 191 */
            }
        }

        /* IMU 行为层: 姿态ID跟随当前配置, Z标定每拍采样, 自稳10Hz更新 */
        {
            const IMU_Angle *ia = IMU_GetAngle();
            float pitch = ia->pitch;
            AttCtrl_SetPose(g_front_rev, g_rear_rev,
                            g_walk_params.stand_h >= STAND_H_HIGH);
            AttCtrl_CalibTick(pitch, ia->roll);
            if (g_calib_pending && !AttCtrl_CalibBusy()) {
                g_calib_pending = 0;
                bluetooth_send("CAL:OK\r\n");  /* 标定完成: 自稳零偏已存 */
            }
            /* 站立自稳: 更新四腿z补偿
             * 激活: 站立静止 / V模式1无倾斜驱动 / W原地抬腿(防对角支撑翘板)
             * W 用 50ms 快拍 + 快速低通 (翘板修正要快); 其余 100ms */
            {
                /* 注意: 空闲态 g_lift_leg=0xFF, 只排除双腿模式(4/5)
                 * W原地抬腿无条件自稳 (标定门控在LevelUpdate内), 不受轮盘标志影响 */
                uint8_t lv_stand = (g_mode == MODE_STAND) && !g_park && !g_rise &&
                                   !g_flip_on && !g_sit &&
                                   !(g_lift_leg == 4u || g_lift_leg == 5u) &&
                                   (AttCtrl_LevelEnabled() || DriveCtrl_LevelAuto());
                uint8_t lv_w = (g_mode == MODE_TROT) && !g_gait_lat &&
                               g_walk_params.step_len == 0.0f;
                g_lv_act = lv_stand || lv_w;
                if ((uint32_t)(uwTick - g_lv_last) >= (lv_w ? 50u : 100u)) {
                    g_lv_last = uwTick;
                    AttCtrl_LevelUpdate(pitch, ia->roll, g_walk_params.stand_h,
                                        g_lv_act, lv_w, g_lv_dz);
                }
            }
        }

        if (g_mode == MODE_STAND || g_mode == MODE_TROT || g_mode == MODE_STEP) {
            /* 目标站高变化: 上升(低趴站起, 大轮负载重)标记慢速, 下降保持原手感 */
            if (g_walk_params.stand_h != g_stand_h_prev) {
                g_rise_slow = (g_walk_params.stand_h > g_stand_h_prev) ? 1 : 0;
                g_stand_h_prev = g_walk_params.stand_h;
            }
            /* 平滑速率: 收纳/站起最慢; 低趴升站慢速(0.04≈1.5s); 翻膝用原速(时序对齐) */
            float rate = (g_park || g_rise) ? 0.008f
                       : ((g_mode == MODE_STAND)
                          ? ((g_rise_slow && !g_flip_on) ? 0.04f : 0.12f)
                          : ((g_walk_params.step_len == 0.0f) ? 0.40f : 0.20f));  /* W原地抬腿跟随更快 */
            uint16_t angles[12];

            for (uint8_t leg = 0; leg < 4; leg++) {
                float d_leg = (leg == 0 || leg == 2) ? -LEG_HIP_D : LEG_HIP_D;
                uint16_t deg[3];

                if (g_mode == MODE_STAND) {
                    float x_leg;
                    uint8_t leg_bit = (leg < 2) ? 1 : 2;
                    if (g_flip_on && (g_flip_mask & leg_bit)) {
                        /* 翻膝机动: 该腿组足端伸到直腿点再收回, 中点翻转膝分支 */
                        float x0  = (leg < 2) ? g_flip_x0f : g_flip_x0r;
                        float sgn = (leg < 2) ? 1.0f : -1.0f;   /* 前腿往+伸, 后腿往-伸 */
                        uint8_t rev_new = (leg < 2) ? g_flip_revf : g_flip_revr;
                        uint8_t rev_old = (leg < 2) ? g_front_rev : g_rear_rev;
                        float seg = (float)FLIP_SEG_MS / 1000.0f;
                        float t   = (float)(uwTick - g_flip_t0) / 1000.0f;
                        if (t >= 2.0f * seg) {
                            /* 完成 (由第一条翻膝腿触发一次) */
                            g_flip_on = 0;
                            if (g_flip_mask & 1) {
                                g_front_rev = g_flip_revf;
                                LegIK_SetFrontReversed(g_flip_revf);
                            }
                            if (g_flip_mask & 2) {
                                g_rear_rev = g_flip_revr;
                                LegIK_SetRearReversed(g_flip_revr);
                            }
                            if (g_flip_post == 1)      g_walk_params.stand_h = STAND_H_L_FRONT;
                            else if (g_flip_post == 2) g_walk_params.stand_h = STAND_H_HIGH;
                            else if (g_flip_post == 3) {
                                g_walk_t0 = uwTick;
                                g_mode = MODE_TROT;
                            }
                            else if (g_flip_post == 4) {
                                g_walk_t0 = uwTick;      /* 翻膝完成后启动横移走 */
                                g_mode = MODE_TROT;
                            }
                            else if (g_flip_post == 5) {
                                g_walk_params.stand_h = PARK_H;  /* 翻完慢速趴到贴地 */
                                g_park = 1;
                            }
                            else if (g_flip_post == 7) {
                                g_sit = 1;   /* 翻完进入坐姿 */
                            }
                            else if (g_flip_post == 8) {
                                g_walk_params.stand_h = g_flip_post_h;  /* 翻完降到 H: 指定高度 */
                            }
                            x_leg = StandFootX(leg);
                        } else if (t < seg) {
                            float u = t / seg;          /* 第一段: 旧分支伸腿 */
                            if (leg < 2) LegIK_SetFrontReversed(rev_old);
                            else         LegIK_SetRearReversed(rev_old);
                            x_leg = x0 + (sgn * g_flip_xm - x0) * u;
                        } else {
                            float u = (t - seg) / seg;  /* 第二段: 新分支收腿 */
                            if (leg < 2) LegIK_SetFrontReversed(rev_new);
                            else         LegIK_SetRearReversed(rev_new);
                            x_leg = sgn * g_flip_xm + (x0 - sgn * g_flip_xm) * u;
                        }
                    } else if (g_lift_leg == leg) {
                        /* 单腿抬腿 (N:命令): 足端x由状态机给 */
                        x_leg = LegLiftX();
                    } else {
                        /* 站立: 足端 = 前移修正 + 低趴外伸 + 单腿零位修正 + 抬腿前伸记忆 */
                        x_leg = StandFootX(leg) + g_walk_params.foot_x_corr[leg] +
                                g_leg_fwd[leg];
                    }
                    /* 倾斜平衡: 足端 z 差动
                     * pitch>0=低头: 前腿z小(前低) 后腿z大(后高)
                     * roll>0=右倾: 右腿z小(右低) 左腿z大(左高) ← 向弯内压 */
                    {
                        float tp, tr;
                        DriveCtrl_GetTilt(&tp, &tr);
                        float z_leg = g_walk_params.stand_h;
                        if (g_sit) {
                            z_leg = (leg < 2) ? SIT_Z_F : SIT_Z_R;  /* 坐姿固定z (不叠加倾斜) */
                        } else if (LegLiftActive(leg)) {
                            /* 抬腿状态机: z由状态机给, 不叠加倾斜/自稳 */
                            z_leg = LegLiftZ(leg, g_walk_params.stand_h);
                        } else if (g_lift_leg == 4u || g_lift_leg == 5u) {
                            /* 上台阶双腿模式: 支撑腿不叠加倾斜/自稳 (身体需自然俯仰) */
                            z_leg = g_walk_params.stand_h;
                        } else {
                            if (leg < 2)          z_leg -= tp;   /* 前腿 */
                            else                  z_leg += tp;   /* 后腿 */
                            if (leg == 0 || leg == 2) z_leg += tr;  /* 左腿: 右倾时左高 */
                            else                      z_leg -= tr;  /* 右腿: 右倾时右低 */
                        }
                        /* 站立自稳: 四腿z补偿 (过渡/翻膝/收纳/抬腿运动中不叠加, 防IK钳位;
                         * 上台阶双腿模式全程让位) */
                        if (!g_park && !g_rise && !g_flip_on && !g_sit &&
                            !LegLiftActive(leg) &&
                            !(g_lift_leg == 4u || g_lift_leg == 5u))
                            z_leg += g_lv_dz[leg];
                        /* 站起阶段: 足端右移 = 身体左移, 卸载右腿 (载荷给 RL) */
                        float y_leg = d_leg + ((g_rise) ? RISE_CM_Y * RiseCmK() : 0.0f);
                        /* 站姿宽度偏移: 每足向外 (右腿+y, 左腿-y), Y:毫米 在线调 */
                        y_leg += ((leg == 1u || leg == 3u) ? g_stance_w : -g_stance_w);
                        /* 单腿抬腿: 支撑腿重心横移, 远离抬起腿 (重心移进支撑三角形)
                         * 抬左腿(0/2)→身体右移; 抬右腿(1/3)→身体左移
                         * ⚠ 外展IK的y通道反向: 命令正值=身体右移
                         * 抬/放过程随缓动渐入渐出, 前伸着地(相位0)撤除 */
                        if (g_lift_leg != 0xFF && g_lift_leg < 4u && leg != g_lift_leg) {
                            float k = 0.0f;
                            if (g_lift_phase == 2)      k = 1.0f;
                            else if (g_lift_phase == 1) k = LegLiftEase(leg);
                            else if (g_lift_phase == 3) k = 1.0f - LegLiftEase(leg);
                            /* 注意y通道反向 (同W补偿): 命令正=身体右移 */
                            float s = ((g_lift_leg == 0u || g_lift_leg == 2u)
                                       ? LEGLIFT_SHIFT : -LEGLIFT_SHIFT);
                            y_leg += s * k;
                        }
                        LegIK_SolveServo(leg, x_leg, y_leg, z_leg, deg);
                    }
                } else {
                    /* 行走/单步: 足端轨迹 -> IK */
                    float t = (g_mode == MODE_TROT)
                            ? (float)(uwTick - g_walk_t0) / 1000.0f
                            : g_step_t;
                    walk_vec3_t ft;
                    if (g_gait_lat)   /* 横移走: 扫步在 y 方向 (螃蟹步, 抬腿+横扫) */
                        WalkGait_FootTargetLat(leg, t, d_leg, g_lat_dir, &ft);
                    else {
                        WalkGait_FootTarget(leg, t, d_leg, &ft);
                        if (g_walk_params.step_len == 0.0f) {
                            /* W原地抬腿: 命令足端左移=身体右移补偿
                             * ⚠ 外展IK的y通道是反的: 命令+15实际足端往左 → 身体右移
                             * 所以要身体左移必须命令负值 (2026-08-25 实测右后腿内收发现) */
                            ft.y -= g_w_com;
                            /* 站姿宽度偏移 (Y:毫米): W 抬腿同样生效 */
                            ft.y += ((leg == 1u || leg == 3u) ? g_stance_w : -g_stance_w);
                            if (g_lv_act && !WalkGait_IsSwing(leg, t))
                                ft.z += g_lv_dz[leg];   /* 支撑腿z补偿 */
                        }
                    }
                    LegIK_SolveServo(leg, ft.x, ft.y, ft.z, deg);
                }

                const uint8_t idx[3] = { leg, leg + 4, leg + 8 };  /* 舵机{i+1,i+5,i+9} */
                for (int j = 0; j < 3; j++) {
                    g_cmd_deg[idx[j]] += ((float)deg[j] - g_cmd_deg[idx[j]]) * rate;
                    angles[idx[j]] = (uint16_t)(g_cmd_deg[idx[j]] + 0.5f);
                }
            }
            NewServo_BatchControl(angles);
        }
        /* MODE_CALIB: 控制循环不碰舵机 */
    }

  }
  /* USER CODE END 3 */
}

void SystemClock_Config(void)
{
  RCC_OscInitTypeDef RCC_OscInitStruct = {0};
  RCC_ClkInitTypeDef RCC_ClkInitStruct = {0};

  /** Supply configuration update enable
  */
  HAL_PWREx_ConfigSupply(PWR_LDO_SUPPLY);

  /** Configure the main internal regulator output voltage
  */
  __HAL_PWR_VOLTAGESCALING_CONFIG(PWR_REGULATOR_VOLTAGE_SCALE0);

  while(!__HAL_PWR_GET_FLAG(PWR_FLAG_VOSRDY)) {}

  /** Initializes the RCC Oscillators according to the specified parameters
  * in the RCC_OscInitTypeDef structure.
  */
  RCC_OscInitStruct.OscillatorType = RCC_OSCILLATORTYPE_HSI|RCC_OSCILLATORTYPE_LSI;
  RCC_OscInitStruct.HSIState = RCC_HSI_DIV1;
  RCC_OscInitStruct.HSICalibrationValue = RCC_HSICALIBRATION_DEFAULT;
  RCC_OscInitStruct.LSIState = RCC_LSI_ON;
  RCC_OscInitStruct.PLL.PLLState = RCC_PLL_ON;
  RCC_OscInitStruct.PLL.PLLSource = RCC_PLLSOURCE_HSI;
  RCC_OscInitStruct.PLL.PLLM = 4;
  RCC_OscInitStruct.PLL.PLLN = 60;
  RCC_OscInitStruct.PLL.PLLP = 2;
  RCC_OscInitStruct.PLL.PLLQ = 2;
  RCC_OscInitStruct.PLL.PLLR = 2;
  RCC_OscInitStruct.PLL.PLLRGE = RCC_PLL1VCIRANGE_3;
  RCC_OscInitStruct.PLL.PLLVCOSEL = RCC_PLL1VCOWIDE;
  RCC_OscInitStruct.PLL.PLLFRACN = 0;
  if (HAL_RCC_OscConfig(&RCC_OscInitStruct) != HAL_OK)
  {
    Error_Handler();
  }

  /** Initializes the CPU, AHB and APB buses clocks
  */
  RCC_ClkInitStruct.ClockType = RCC_CLOCKTYPE_HCLK|RCC_CLOCKTYPE_SYSCLK
                              |RCC_CLOCKTYPE_PCLK1|RCC_CLOCKTYPE_PCLK2
                              |RCC_CLOCKTYPE_D3PCLK1|RCC_CLOCKTYPE_D1PCLK1;
  RCC_ClkInitStruct.SYSCLKSource = RCC_SYSCLKSOURCE_PLLCLK;
  RCC_ClkInitStruct.SYSCLKDivider = RCC_SYSCLK_DIV1;
  RCC_ClkInitStruct.AHBCLKDivider = RCC_HCLK_DIV2;
  RCC_ClkInitStruct.APB3CLKDivider = RCC_APB3_DIV2;
  RCC_ClkInitStruct.APB1CLKDivider = RCC_APB1_DIV2;
  RCC_ClkInitStruct.APB2CLKDivider = RCC_APB2_DIV2;
  RCC_ClkInitStruct.APB4CLKDivider = RCC_APB4_DIV2;

  if (HAL_RCC_ClockConfig(&RCC_ClkInitStruct, FLASH_LATENCY_4) != HAL_OK)
  {
    Error_Handler();
  }
}

/* USER CODE BEGIN 4 */

static char     g_line_buf[12];
static uint8_t  g_line_idx = 0;

/* 解析指针处连续数字, 返回数值并推进指针 */
static int s_parse_num(const char **p)
{
    int v = 0;
    while (**p >= '0' && **p <= '9') { v = v * 10 + (int)(**p - '0'); (*p)++; }
    return v;
}

#if 1   /* ==== 舵机校准: 重装舵机臂后重新标定用 (标定完可改回 0) ==== */
static uint8_t  g_calib_servo   = 1;     /* 当前校准舵机号 1~12 */
static uint16_t g_pending_angle = 0;
static uint8_t  g_pending_srv   = 0;
static uint8_t  g_pending       = 0;

static int s_atoi(const char *s) {
    int v = 0;
    while (*s >= '0' && *s <= '9') v = v * 10 + (int)(*s++ - '0');
    return v;
}
#endif

/* UART 错误自愈: 上电时序噪声(模块复位输出低电平)会产生 FE/ORE,
 * HAL 错误路径会停掉接收链, 必须在这里清错误+重装接收 */
void HAL_UART_ErrorCallback(UART_HandleTypeDef *huart)
{
    if (huart->Instance == USART2) {
        __HAL_UART_CLEAR_OREFLAG(huart);
        __HAL_UART_CLEAR_FEFLAG(huart);
        __HAL_UART_CLEAR_PEFLAG(huart);
        __HAL_UART_CLEAR_NEFLAG(huart);
        huart->RxState = HAL_UART_STATE_READY;
        HAL_UART_Receive_IT(huart, &imu_rx_byte, 1);
    }
    else if (huart->Instance == USART3) {
        __HAL_UART_CLEAR_OREFLAG(huart);
        __HAL_UART_CLEAR_FEFLAG(huart);
        huart->RxState = HAL_UART_STATE_READY;
        HAL_UART_Receive_IT(huart, &bt_rx_byte, 1);
    }
}

void HAL_UART_RxCpltCallback(UART_HandleTypeDef *huart)
{
    if (huart->Instance == USART2) {
        /* IMU 字节流: 喂解析器 (0x55 帧协议) */
        IMU_ParseByte(imu_rx_byte);
        HAL_UART_Receive_IT(&huart2, &imu_rx_byte, 1);
        return;
    }
    char c = (char)bt_rx_byte;

    if (c == '\r' || c == '\n') {
        if (g_line_idx > 0) {
            g_line_buf[g_line_idx] = '\0';
            char f = g_line_buf[0];
            static char msg[32];

            if (f == 'G' || f == 'g') {
                if (g_line_buf[1] == ':') {
                    /* G:水平:俯仰 → 云台舵机 (0~270°, 俯仰缺省135; 与 G 站姿区分: 带冒号) */
                    const char *p = g_line_buf + 2;
                    int pan = s_parse_num(&p);
                    int tilt = 135;
                    if (*p == ':') { p++; tilt = s_parse_num(&p); }
                    Gimbal_Set(GIMBAL_PAN,  (uint16_t)pan);
                    Gimbal_Set(GIMBAL_TILT, (uint16_t)tilt);
                    snprintf(msg, sizeof(msg), "GM:%d,%d\r\n",
                             (int)Gimbal_Get(GIMBAL_PAN), (int)Gimbal_Get(GIMBAL_TILT));
                    bluetooth_send(msg);
                } else {
                    /* 站立 = 狗高站姿 280 (前后正常膝, 若反折先翻膝再升), 收纳姿态直接站起 */
                    g_flip_on = 0; g_flip_start = 0;
                    LegLiftReset();
                    g_park = 0; g_sit = 0;
                    g_booted = 0;
                    g_flip_mask = 0;
                    if (g_front_rev) g_flip_mask |= 1;
                    if (g_rear_rev)  g_flip_mask |= 2;
                    g_flip_revf = 0; g_flip_revr = 0;
                    if (g_flip_mask) {
                        if (g_walk_params.stand_h < FLIP_H)
                            g_walk_params.stand_h = FLIP_H;   /* 先到翻膝高度 */
                        g_flip_post = 2;                      /* 翻完升 280 */
                        g_flip_start = uwTick + FLIP_SETTLE_MS;
                    } else {
                        g_walk_params.stand_h = STAND_H_HIGH;
                    }
                    g_mode = MODE_STAND;
                    bluetooth_send("STAND...\r\nOK:STAND\r\n");
                }
            }
            else if (f == 'T' || f == 't') {
                /* 连续 Trot: T 前进 / T:-1 倒着走 (负步幅+轮反向助走)
                 * 注意: s_parse_num 不处理负号, 方向直接看符号字符 */
                int back = (g_line_buf[1] == ':' && g_line_buf[2] == '-') ? 1 : 0;
                TrotStart(SHIFT_OFF, 10, (uint8_t)back,
                          back ? "TROTB\r\n" : "TROT\r\n");
            }
            else if (f == 'E' || f == 'e') {
                /* 转圈动作: trot + 重心横移 (定死15mm); E/E:1 顺时针, E:0 逆时针 */
                const char *p = g_line_buf + 1;
                int sign = 1;
                if (*p == ':') {
                    p++;
                    if (*p == '0') sign = -1;
                }
                g_shift_sign = sign;
                snprintf(msg, sizeof(msg), "SWAY:%d\r\n", sign);
                TrotStart(SHIFT_IK, 0, 0, msg);   /* 原地转圈: 不助走 */
            }
            else if (f == 'F' || f == 'f') {
                /* 横移走 (螃蟹步): 四腿外展横向扫步, F 或 F:1 向右, F:0 向左
                 * 强制狗姿态 280 (低趴反折膝抬腿会钳FL小腿), 抬腿50mm防拖地 */
                const char *p = g_line_buf + 1;
                int dir = 1;
                if (*p == ':') {
                    p++;
                    if (*p == '0') dir = -1;
                }
                g_flip_on = 0; g_flip_start = 0;
                DriveCtrl_Reset();
                g_booted = 0;
                g_shift_mode = SHIFT_OFF;
                g_gait_lat = 1;
                g_lat_dir  = dir;
                g_walk_params.stand_h  = STAND_H_HIGH;   /* 强制狗姿态 280 */
                g_walk_params.step_len = 30.0f;          /* 横移步宽 30mm */
                g_walk_params.step_h   = 40.0f;          /* 横移抬腿 40mm (原地抬腿结合版) */
                for (int i = 0; i < 4; i++)
                    Motor_Stop((uint8_t)i);
                if (g_front_rev || g_rear_rev) {
                    /* 反折膝抬腿会钳位: 先翻膝回正常再开走 */
                    g_flip_mask = (g_front_rev ? 1 : 0) | (g_rear_rev ? 2 : 0);
                    g_flip_revf = 0;
                    g_flip_revr = 0;
                    g_flip_post = 4;
                    g_flip_start = uwTick + FLIP_SETTLE_MS;
                } else {
                    g_walk_t0 = uwTick;
                    g_mode = MODE_TROT;
                }
                snprintf(msg, sizeof(msg), "SIDE:%d\r\n", dir);
                bluetooth_send(msg);
            }
            else if (f == 'W' || f == 'w') {
                /* 越障模式: 原地对角抬腿 50mm (不动轮, 前进由 V 无倾斜轮盘控制)
                 * 自稳自动跟随 (需Z标定) + 重心左移补偿 (W:毫米 在线调, 默认15)
                 * W 运行中发 W:毫米 只改补偿量: 不重置相位、不停轮 (APP 滑块实时调) */
                uint8_t w_tune = 0;
                if (g_line_buf[1] == ':') {
                    const char *wp = g_line_buf + 2;
                    int wv = s_parse_num(&wp);
                    if (wv >= -40 && wv <= 40) g_w_com = (float)wv;
                    snprintf(msg, sizeof(msg), "WCOM:%d\r\n", (int)g_w_com);
                    bluetooth_send(msg);
                    w_tune = (g_mode == MODE_TROT &&
                              g_walk_params.step_len == 0.0f &&
                              !g_flip_on && !g_flip_start);
                }
                if (!w_tune) {
                    g_flip_on = 0; g_flip_start = 0;
                    DriveCtrl_Reset();
                    g_booted = 0;
                    g_shift_mode = SHIFT_OFF;              /* 无重心横移 */
                    g_gait_lat = 0;
                    g_walk_params.stand_h = STAND_H_HIGH;  /* 高站姿: 抬腿明显 */
                    g_walk_params.step_h   = 50.0f;        /* 抬腿 50mm: 70mm 时 RR大腿266°/RL小腿261° 贴270极限抬不动 */
                    g_walk_params.step_len = 0.0f;         /* 原地抬腿 (前进交给轮盘) */
                    if (g_front_rev || g_rear_rev) {
                        /* 反折分支抬70mm会钳小腿: 先翻膝回正常再开走 */
                        g_flip_mask = (g_front_rev ? 1 : 0) | (g_rear_rev ? 2 : 0);
                        g_flip_revf = 0;
                        g_flip_revr = 0;
                        g_flip_post = 3;
                        g_flip_start = uwTick + FLIP_SETTLE_MS;
                    } else {
                        g_walk_t0 = uwTick;
                        g_mode = MODE_TROT;
                    }
                    bluetooth_send("CLIMB\r\n");
                }
            }
            else if (f == 'A' || f == 'a') {
                if (g_mode != MODE_STEP) {   /* 首次按A: 进入单步模式, 相位0 */
                    g_mode = MODE_STEP;
                    g_step_t = 0.0f;
                    g_step_cnt = 0;
                } else {                     /* 之后每按: 相位 +1/4 周期 */
                    g_step_t += g_walk_params.period * 0.25f;
                    g_step_cnt = (g_step_cnt + 1) & 3;
                }
                snprintf(msg, sizeof(msg), "PH:%d\r\n", g_step_cnt * 90);
                bluetooth_send(msg);
            }
            else if ((f == 'H' || f == 'h') && g_line_buf[1] == ':') {
                /* H:高度 正常膝低站姿 (爬陡坡用: 站得越低自稳可补偿坡度越大)
                 * 缺省230, 范围200~280; 单独 H 仍是280高站姿 */
                const char *p = g_line_buf + 2;
                int h = s_parse_num(&p);
                if (h < 200 || h > 280) h = 230;
                g_flip_on = 0; g_flip_start = 0;
                LegLiftReset();
                g_park = 0; g_sit = 0;
                g_booted = 0;
                g_flip_mask = 0;
                if (g_front_rev) g_flip_mask |= 1;
                if (g_rear_rev)  g_flip_mask |= 2;
                g_flip_revf = 0; g_flip_revr = 0;
                if (g_flip_mask) {
                    g_walk_params.stand_h = FLIP_H;   /* 翻膝固定在240做 (膝离地有保证) */
                    g_flip_post_h = (float)h;
                    g_flip_post = 8;                  /* 翻完降到指定高度 */
                    g_flip_start = uwTick + FLIP_SETTLE_MS;
                } else {
                    g_walk_params.stand_h = (float)h;
                }
                g_mode = MODE_STAND;
                snprintf(msg, sizeof(msg), "HIGH:%d\r\n", h);
                bluetooth_send(msg);
            }
            else if (f == 'H' || f == 'h') {
                /* 狗姿态高站姿 280: 前后腿都正常分支 */
                g_flip_on = 0; g_flip_start = 0;
                LegLiftReset();
                g_park = 0; g_sit = 0;
                g_booted = 0;
                g_flip_mask = 0;
                if (g_front_rev) g_flip_mask |= 1;
                if (g_rear_rev)  g_flip_mask |= 2;
                g_flip_revf = 0; g_flip_revr = 0;
                if (g_flip_mask) {
                    if (g_walk_params.stand_h < FLIP_H)
                        g_walk_params.stand_h = FLIP_H;   /* 先到翻膝高度 */
                    g_flip_post = 2;                      /* 翻完升 280 */
                    g_flip_start = uwTick + FLIP_SETTLE_MS;
                } else {
                    g_walk_params.stand_h = STAND_H_HIGH;
                }
                g_mode = MODE_STAND;
                bluetooth_send("HIGH\r\n");
            }
            else if (f == 'K' || f == 'k') {
                /* 膝盖往前顶高站姿 280: 前腿反折, 后腿正常 */
                g_flip_on = 0; g_flip_start = 0;
                LegLiftReset();
                g_park = 0; g_sit = 0;
                g_walk_params.stand_h = STAND_H_HIGH;
                g_flip_mask = 0;
                if (!g_front_rev) g_flip_mask |= 1;
                if (g_rear_rev)   g_flip_mask |= 2;
                g_flip_revf = 1; g_flip_revr = 0;
                if (g_flip_mask) {
                    g_flip_post = 0;                      /* 翻完保持 280 */
                    g_flip_start = uwTick + FLIP_SETTLE_MS;
                }
                g_mode = MODE_STAND;
                bluetooth_send("KNEE\r\n");
            }
            else if ((f == 'L' || f == 'l') && g_line_buf[1] == ':') {
                /* L:1/L:0 站立自稳开关 (绝对值: L:1=强制开, L:0=总关+清跟随残留;
                 * 裸L:兼容切换) —— 绝对值避免APP状态与固件错位 */
                uint8_t r;
                if (g_line_buf[2] == '1')      r = AttCtrl_LevelSet(1);
                else if (g_line_buf[2] == '0') r = AttCtrl_LevelSet(0);
                else                           r = AttCtrl_LevelToggle();
                if (r == 2)      bluetooth_send("LV:NOCAL\r\n");
                else if (r == 0) bluetooth_send("LV:ON\r\n");
                else {
                    DriveCtrl_SetNoTilt(0);
                    DriveCtrl_SetLevelAuto(0);
                    bluetooth_send("LV:OFF\r\n");
                }
            }
            else if (f == 'L' || f == 'l') {
                /* 低趴 240: 前腿反折, 后腿正常 */
                g_flip_on = 0; g_flip_start = 0;
                LegLiftReset();
                g_park = 0; g_sit = 0;
                g_booted = 0;
                g_flip_mask = 0;
                if (!g_front_rev) g_flip_mask |= 1;
                if (g_rear_rev)   g_flip_mask |= 2;
                g_flip_revf = 1; g_flip_revr = 0;
                if (g_flip_mask) {
                    g_walk_params.stand_h = FLIP_H;       /* 先到翻膝高度 */
                    g_flip_post = 1;                      /* 翻完趴到 LOW */
                    g_flip_start = uwTick + FLIP_SETTLE_MS;
                } else {
                    g_walk_params.stand_h = STAND_H_L_FRONT;  /* 已是目标分支: 直接趴 */
                }
                g_mode = MODE_STAND;
                bluetooth_send("LOW\r\n");
            }
            else if ((f == 'M' || f == 'm') &&
                     !(g_line_buf[1] >= '0' && g_line_buf[1] <= '9')) {
                /* 后腿膝盖往前突低趴 240: 前腿狗腿(正常), 后腿反折, 重心集中
                 * 注意: 第二字节是数字时放行给后面的 M0:50:1 电机命令 */
                g_flip_on = 0; g_flip_start = 0;
                LegLiftReset();
                g_park = 0; g_sit = 0;
                g_booted = 0;
                g_flip_mask = 0;
                if (g_front_rev) g_flip_mask |= 1;        /* 前腿翻回正常 */
                if (!g_rear_rev) g_flip_mask |= 2;        /* 后腿翻成反折 */
                g_flip_revf = 0; g_flip_revr = 1;
                if (g_flip_mask) {
                    g_walk_params.stand_h = FLIP_H;
                    g_flip_post = 1;
                    g_flip_start = uwTick + FLIP_SETTLE_MS;
                } else {
                    g_walk_params.stand_h = STAND_H_LOW;
                }
                g_mode = MODE_STAND;
                bluetooth_send("REAR\r\n");
            }
            else if (f == 'P' || f == 'p') {
                /* 后腿膝盖往前突高站姿 280: 前腿狗腿(正常), 后腿反折 */
                g_flip_on = 0; g_flip_start = 0;
                LegLiftReset();
                g_park = 0; g_sit = 0;
                g_walk_params.stand_h = STAND_H_HIGH;
                g_flip_mask = 0;
                if (g_front_rev) g_flip_mask |= 1;
                if (!g_rear_rev) g_flip_mask |= 2;
                g_flip_revf = 0; g_flip_revr = 1;
                if (g_flip_mask) {
                    g_flip_post = 0;                      /* 翻完保持 280 */
                    g_flip_start = uwTick + FLIP_SETTLE_MS;
                }
                g_mode = MODE_STAND;
                bluetooth_send("REARH\r\n");
            }
            else if (f == 'C' || f == 'c') {
                /* 收纳: 72mm 贴地趴 (前腿反折前伸直x+297/后腿正常后伸直x-297)
                 * 慢速缓降约2~3s, 断电后肚皮只落~32mm, U 规划式站起 */
                g_flip_on = 0; g_flip_start = 0;
                DriveCtrl_Reset();
                g_rise = 0;
                g_booted = 0;
                g_flip_mask = 0;
                if (!g_front_rev) g_flip_mask |= 1;   /* 前腿翻成反折 */
                if (g_rear_rev)   g_flip_mask |= 2;   /* 后腿翻回正常 */
                g_flip_revf = 1; g_flip_revr = 0;
                if (g_flip_mask) {
                    g_walk_params.stand_h = FLIP_H;
                    g_flip_post = 5;                  /* 翻完进贴地趴 */
                    g_flip_start = uwTick + FLIP_SETTLE_MS;
                } else {
                    g_park = 1;                       /* 直接慢速趴 */
                    g_walk_params.stand_h = PARK_H;
                }
                g_mode = MODE_STAND;
                bluetooth_send("PARK\r\n");
            }
            else if ((f == 'U' || f == 'u') && g_line_buf[1] == ':') {
                /* U:1/U:0 按键页速度档加减 (步进5, 范围10~50), 回 SPD:数值 (APP实时显示)
                 * 按键驾驶中立即生效 (按当前方向重新下发); 裸 U 仍是规划式站起 */
                if (g_line_buf[2] == '1') {
                    if (g_btn_spd < 50) g_btn_spd += 5;
                } else {
                    if (g_btn_spd > 10) g_btn_spd -= 5;
                }
                if (g_btn_driving && g_mode == MODE_STAND) {
                    if (g_btn_mode == 1)
                        DriveCtrl_SetButtonFlat(g_btn_dir, g_btn_spd);
                    else
                        DriveCtrl_SetButton(g_btn_dir, g_btn_spd);
                }
                snprintf(msg, sizeof(msg), "SPD:%d\r\n", (int)g_btn_spd);
                bluetooth_send(msg);
            }
            else if (f == 'U' || f == 'u') {
                /* 规划式站起: 阶段A 收腿+顶升(3.5s缓升到240) → 阶段B 翻膝升280
                 * 收纳中或刚上电(假定在趴姿)可用 */
                g_flip_on = 0; g_flip_start = 0;
                DriveCtrl_Reset();
                uint8_t need_sync = g_booted;   /* 刚上电: 指令角预置是280站姿, 需先同步到趴姿 */
                if (g_park || g_booted) {
                    g_booted = 0;
                    g_rise_h0 = g_park ? g_walk_params.stand_h : PARK_H;
                    g_park = 0; g_sit = 0;
                    g_rise = 1;
                    g_rise_t0 = uwTick;
                    LegIK_SetFrontReversed(1);        /* 阶段A按反折分支 (与趴姿一致) */
                    if (need_sync) {
                        /* 2026-08-21 修复: 上电后按U, 指令角若不先同步到趴姿,
                         * 大腿会从280站姿角爬向趴姿角 → 前腿乱扫 (FL/FR 动作不对称, FR 堵转) */
                        for (int leg = 0; leg < 4; leg++) {
                            float d_leg = (leg == 0 || leg == 2) ? -LEG_HIP_D : LEG_HIP_D;
                            float xp = (leg < 2)
                                     ? g_walk_params.foot_x_shift + PARK_X_F
                                     : g_walk_params.foot_x_shift - PARK_X_R;
                            uint16_t deg[3];
                            LegIK_SolveServo((uint8_t)leg,
                                             xp + g_walk_params.foot_x_corr[leg],
                                             d_leg, PARK_H, deg);
                            g_cmd_deg[leg]     = (float)STAND_POSE[leg][JOINT_ABD];
                            g_cmd_deg[leg + 4] = (float)deg[1];
                            g_cmd_deg[leg + 8] = (float)deg[2];
                        }
                    }
                    g_walk_params.stand_h = g_rise_h0;
                    g_mode = MODE_STAND;
                    bluetooth_send("RISE\r\n");
                } else {
                    bluetooth_send("NOT PARK\r\n");
                }
            }
            else if (f == 'X' || f == 'x') {
                /* 前倾修正: X:毫米 (如 X:20) 正值=足端前移/身体后坐, 站立行走同时生效 */
                const char *p = g_line_buf + 1;
                int sign = 1;
                if (*p == ':') p++;
                if (*p == '-') { sign = -1; p++; }
                int v = s_parse_num(&p);
                if (v >= 0 && v <= 60) {
                    g_walk_params.foot_x_shift = (float)(sign * v);
                    snprintf(msg, sizeof(msg), "XSH:%d\r\n", sign * v);
                    bluetooth_send(msg);
                }
            }
            else if (f == 'D' || f == 'd') {
                /* 方向按键: D:方向[:速度[:模式]]  0=前进 1=后退 2=左前/左转 3=右前/右转
                 * 速度 10~50 (占空比%, 缺省=按键页速度档 g_btn_spd, U:1/U:0 调)
                 * 模式 缺省/0=经典固定倾斜全程保持, S 回平
                 * 模式 1=新按键页: 无倾斜补偿, 转向 20/30 小差速, 自稳跟全局 L:1 走 */
                const char *p = g_line_buf + 1;
                int dir = 0;
                if (*p == ':') { p++; dir = s_parse_num(&p); }
                int spd = g_btn_spd;
                if (*p == ':') { p++; spd = s_parse_num(&p); }
                int mode = 0;
                if (*p == ':') { p++; mode = s_parse_num(&p); }
                if (mode == 1)
                    DriveCtrl_SetButtonFlat((uint8_t)dir, (int8_t)spd);
                else
                    DriveCtrl_SetButton((uint8_t)dir, (int8_t)spd);
                g_btn_dir = (uint8_t)dir;
                g_btn_mode = (uint8_t)mode;
                g_btn_driving = 1;
                g_booted = 0;
                snprintf(msg, sizeof(msg), "DRV:%d:%d\r\n", dir, spd);
                bluetooth_send(msg);
            }
            else if (f == 'V' || f == 'v') {
                /* 摇杆驱动: V:速度:转向[:模式] (-50~+50, 速度负=后退, 转向负=左/正=右)
                 * 模式 缺省/0 = 经典倾斜平衡; 1 = 无倾斜补偿 + 高站姿280 + 自稳保持 (第二套轮盘)
                 * 高频流不回显; 差速+斜坡+倾斜平衡在 drive_ctrl 内处理 */
                const char *p = g_line_buf + 1;
                int sign = 1;
                if (*p == ':') p++;
                if (*p == '-') { sign = -1; p++; }
                int sp = s_parse_num(&p);
                if (sign < 0) sp = -sp;
                sign = 1;
                int st = 0;
                if (*p == ':') {
                    p++;
                    if (*p == '-') { sign = -1; p++; }
                    st = s_parse_num(&p);
                    if (sign < 0) st = -st;
                }
                int mode = 0;
                if (*p == ':') { p++; mode = s_parse_num(&p); }

                if (mode == 1) {
                    /* 无倾斜补偿模式: 要求高站姿 H (自稳仅 H/K 生效)
                     * 反折膝先翻回 H, 翻完前的驱动命令忽略 (高频流会重复触发, 防重入) */
                    if (g_front_rev || g_rear_rev) {
                        if (!g_flip_on && !g_flip_start) {
                            g_park = 0; g_sit = 0; g_rise = 0; g_booted = 0;
                            g_flip_mask = (g_front_rev ? 1 : 0) | (g_rear_rev ? 2 : 0);
                            g_flip_revf = 0; g_flip_revr = 0;
                            if (g_walk_params.stand_h < FLIP_H)
                                g_walk_params.stand_h = FLIP_H;
                            g_flip_post = 2;                 /* 翻完升 280 */
                            g_flip_start = uwTick + FLIP_SETTLE_MS;
                            bluetooth_send("FLIP\r\n");
                        }
                        DriveCtrl_Reset();
                    } else if (!g_park && !g_rise && !g_sit) {
                        /* 已在高站姿: 无倾斜驱动 + 自稳自动跟随 (需先 Z 标定 H) */
                        DriveCtrl_SetNoTilt(1);
                        DriveCtrl_SetLevelAuto(1);
                        DriveCtrl_SetCmd((int8_t)sp, (int8_t)st);
                        g_btn_driving = 0;   /* 摇杆接管 */
                        g_booted = 0;
                    }
                } else {
                    DriveCtrl_SetNoTilt(0);
                    DriveCtrl_SetLevelAuto(0);
                    DriveCtrl_SetCmd((int8_t)sp, (int8_t)st);
                    g_btn_driving = 0;
                    g_booted = 0;
                }
            }
            else if (f == 'J' || f == 'j') {
                /* 编码器转速上报开关: 10Hz E,帧 (帧尾520) */
                g_enc_stream = !g_enc_stream;
                bluetooth_send(g_enc_stream ? "J:ON\r\n" : "J:OFF\r\n");
            }
            else if (f == 'O' || f == 'o') {
                /* 坐姿: 前腿竖直伸直 + 后腿反折深蹲 (狗坐造型, 车身自然抬头约10°) */
                g_flip_on = 0; g_flip_start = 0;
                DriveCtrl_Reset();
                g_park = 0; g_rise = 0; g_booted = 0;
                g_walk_params.stand_h = FLIP_H;   /* 240: 后腿翻膝高度 */
                if (g_rear_rev == 0) {
                    g_flip_mask = 2;               /* 只翻后腿 */
                    g_flip_revf = g_front_rev;     /* 前腿分支不动 */
                    g_flip_revr = 1;
                    g_flip_post = 7;               /* 翻完进入坐姿 */
                    g_flip_start = uwTick + FLIP_SETTLE_MS;
                } else {
                    g_sit = 1;                     /* 后腿已是反折: 直接坐 */
                }
                g_mode = MODE_STAND;
                bluetooth_send("SIT\r\n");
            }
            else if (f == 'I' || f == 'i') {
                /* IMU 上报开关: 10Hz 角度流 (帧尾520) */
                g_imu_stream = !g_imu_stream;
                bluetooth_send(g_imu_stream ? "IMU:ON\r\n" : "IMU:OFF\r\n");
                g_imu_diag = 1;  /* 诊断挪到主循环发 (ISR 里连发两条会卡 DMA) */
            }
            else if (f == 'Z' || f == 'z') {
                /* 自稳标定: 采样2s存当前姿态 pitch/roll 零偏 (放平地保持静止) */
                AttCtrl_CalibStart();
                g_calib_pending = 1;
                bluetooth_send("CALIB...\r\n");
            }
            else if (f == 'R' || f == 'r') {
                /* 一键滚动: 四电机 30% 占空比正转 (A/B方向已在Motor_Set内纠正) */
                DriveCtrl_Reset();   /* 接管电机前先复位摇杆驱动 */
                g_booted = 0;
                for (int i = 0; i < 4; i++)
                    Motor_Set((uint8_t)i, 30, 1);
                bluetooth_send("ROLL\r\n");
            }
            else if (f == 'B' || f == 'b') {
                /* 一键后退: 四电机 30% 占空比反转 */
                DriveCtrl_Reset();
                g_booted = 0;
                for (int i = 0; i < 4; i++)
                    Motor_Set((uint8_t)i, 30, 0);
                bluetooth_send("BACK\r\n");
            }
            else if (f == 'S' || f == 's') {
                /* 一键停: 四电机全停 */
                DriveCtrl_Reset();
                bluetooth_send("STOP\r\n");
            }
            else if (f == 'M' || f == 'm') {
                /* 电机控制: M电机号:速度[:方向]
                 * 电机号 0~3 = A~D, 速度 0~100, 方向 1=正转 0=反转(缺省1) */
                const char *p = g_line_buf + 1;   /* 跳过 M */
                int m  = s_parse_num(&p);
                if (*p == ':') p++;
                int sp = s_parse_num(&p);
                int dir = 1;
                if (*p == ':') { p++; dir = s_parse_num(&p); }
                if (m >= 0 && m <= 3 && sp >= 0 && sp <= 100) {
                    if (sp == 0)
                        Motor_Stop((uint8_t)m);
                    else
                        Motor_Set((uint8_t)m, (uint8_t)sp, (uint8_t)(dir ? 1 : 0));
                    snprintf(msg, sizeof(msg), "M%c:%d:%d\r\n",
                             'A' + m, sp, dir ? 1 : 0);
                    bluetooth_send(msg);
                }
            }
            else if ((f == 'N' || f == 'n') && g_line_buf[1] == ':') {
                /* N:腿:动作 抬腿 (动作 1=抬起 0=慢慢放下)
                 * 腿 0=FL 1=FR 2=RL 3=RR (单腿: 前伸80mm, 前伸记忆, 可依次迈出)
                 * 腿 4=前双腿 5=后双腿 (上台阶: 50mm直抬, 交错0.3s, 按住抬/松开放)
                 * 互斥: 仅空中腿阻塞; 落地即释放; 姿态命令(G等)全部滚回 */
                const char *p = g_line_buf + 2;
                int leg = s_parse_num(&p);
                int act = 0;
                if (*p == ':') { p++; act = s_parse_num(&p); }
                if (leg >= 0 && leg <= 5) {
                    if (act == 1) {
                        /* 抬起 */
                        if (g_lift_leg == (uint8_t)leg) {
                            snprintf(msg, sizeof(msg), "LG:%d,1\r\n", leg);  /* 已在抬 (按住重复发确认) */
                            bluetooth_send(msg);
                        } else if (g_lift_leg != 0xFF) {
                            bluetooth_send("LG:BUSY\r\n");   /* 有腿在空中 */
                        } else if (!(g_mode == MODE_STAND && !g_park && !g_rise &&
                                     !g_flip_on && !g_sit)) {
                            bluetooth_send("LG:NO\r\n");   /* 非站立/过渡中不可用 */
                        } else {
                            g_lift_leg   = (uint8_t)leg;
                            g_lift_phase = 1;
                            g_lift_t0    = uwTick;
                            if (leg <= 3) {
                                g_lift_x0 = StandFootX((uint8_t)leg) +
                                            g_walk_params.foot_x_corr[leg] +
                                            g_leg_fwd[leg];
                                /* 已在前伸上限(80mm)的腿: 原地抬, 不再前伸 */
                                g_lift_dx = (g_leg_fwd[leg] < LEGLIFT_FWD - 0.5f)
                                            ? LEGLIFT_FWD : 0.0f;
                            } else {
                                g_lift_dx = 0.0f;   /* 双腿直抬: x 不动 */
                            }
                            snprintf(msg, sizeof(msg), "LG:%d,1\r\n", leg);
                            bluetooth_send(msg);
                        }
                    } else {
                        /* 放下 */
                        if (g_lift_leg == (uint8_t)leg && g_lift_phase != 3) {
                            /* 抬起中/悬空: 从当前位置平滑转放下 */
                            uint8_t leg0 = (leg >= 4) ? (uint8_t)(leg == 4 ? 0 : 2)
                                                      : (uint8_t)leg;
                            float znow = LegLiftZ(leg0, g_walk_params.stand_h);
                            float xnow = LegLiftX();
                            g_lift_phase = 3;
                            g_lift_z3 = znow;
                            g_lift_x3 = xnow;
                            g_lift_t0  = uwTick;
                            snprintf(msg, sizeof(msg), "LG:%d,0\r\n", leg);
                            bluetooth_send(msg);
                        } else if (g_lift_leg == 0xFF) {
                            snprintf(msg, sizeof(msg), "LG:%d,0\r\n", leg);  /* 已放下 */
                            bluetooth_send(msg);
                        } else {
                            bluetooth_send("LG:BUSY\r\n");   /* 另一条腿在空中 */
                        }
                    }
                }
            }
            else if ((f == 'Y' || f == 'y') && g_line_buf[1] == ':') {
                /* Y:毫米 站姿宽度偏移 (±40, 默认0): 每足向外偏移, 支撑面加宽
                 * 崎岖地面抗侧倾测试 + 外展y通道方向实测; 裸 Y 仍是校准确认 */
                const char *p = g_line_buf + 2;
                int sign = 1;
                if (*p == '-') { sign = -1; p++; }
                int v = s_parse_num(&p);
                if (v >= 0 && v <= 40) {
                    g_stance_w = (float)(sign * v);
                    snprintf(msg, sizeof(msg), "WID:%d\r\n", sign * v);
                    bluetooth_send(msg);
                }
            }
#if 1   /* ==== 舵机校准命令: 重装舵机臂后重新标定用 (标定完可改回 0) ==== */
            else if (f == 'Y' || f == 'y') {
                if (g_pending && g_pending_srv >= 1 && g_pending_srv <= 12) {
                    NewServo_SetAngle(g_pending_srv, g_pending_angle);
                    g_calib_servo = g_pending_srv;
                    snprintf(msg, sizeof(msg), "OK:S%d:%d\r\n", g_calib_servo, g_pending_angle);
                    bluetooth_send(msg);
                    g_pending = 0;
                }
                g_line_idx = 0; HAL_UART_Receive_IT(&huart3, &bt_rx_byte, 1); return;
            }
            else if (f == 'N' || f == 'n') {
                g_pending = 0;
                bluetooth_send("CANCEL\r\n");
            }
            else if (f >= '0' && f <= '9') {
                char *col = NULL;
                for (int i = 0; g_line_buf[i]; i++)
                    if (g_line_buf[i] == ':') { col = &g_line_buf[i]; break; }

                if (col) {
                    *col = '\0';
                    int s = s_atoi(g_line_buf), a = s_atoi(col + 1);
                    if (s >= 1 && s <= 12 && a >= 0 && a <= 270) {
                        g_pending_srv = (uint8_t)s; g_pending_angle = (uint16_t)a; g_pending = 1;
                        snprintf(msg, sizeof(msg), "SET:S%d:%d?\r\n", s, a); bluetooth_send(msg);
                    }
                } else {
                    int v = s_atoi(g_line_buf);
                    if (v >= 1 && v <= 12) {
                        g_calib_servo = (uint8_t)v; g_pending = 0;
                        snprintf(msg, sizeof(msg), "SW:S%d\r\n", v); bluetooth_send(msg);
                    } else if (v >= 0 && v <= 270) {
                        g_pending_srv = g_calib_servo; g_pending_angle = (uint16_t)v; g_pending = 1;
                        snprintf(msg, sizeof(msg), "SET:S%d:%d?\r\n", g_calib_servo, v); bluetooth_send(msg);
                    }
                }
            }
#endif
            else {
                /* 调试: 回显无法识别的命令 */
                snprintf(msg, sizeof(msg), "UNK:%s\r\n", g_line_buf);
                bluetooth_send(msg);
            }
            g_line_idx = 0;
        }
    } else if ((c >= '0' && c <= '9') || c == ':' || c == '-') {
        if (g_line_idx < sizeof(g_line_buf) - 1) g_line_buf[g_line_idx++] = c;
    } else if ((c >= 'A' && c <= 'Z') || (c >= 'a' && c <= 'z')) {
        if (g_line_idx == 0) g_line_buf[g_line_idx++] = c;
    }
    HAL_UART_Receive_IT(&huart3, &bt_rx_byte, 1);
}
/* USER CODE END 4 */

 /* MPU Configuration */
/* 必做修复2 (每次 Generate 后手动替换):
 * D1/D2 RAM 全部非缓存 — 蓝牙 TX 走 DMA, D-Cache 一致性依赖此配置 */

void MPU_Config(void)
{
  MPU_Region_InitTypeDef MPU_InitStruct = {0};
  HAL_MPU_Disable();

  /* D2 SRAM 区: 非缓存 */
  MPU_InitStruct.Enable = MPU_REGION_ENABLE;
  MPU_InitStruct.Number = MPU_REGION_NUMBER0;
  MPU_InitStruct.BaseAddress = 0x30000000;
  MPU_InitStruct.Size = MPU_REGION_SIZE_512KB;
  MPU_InitStruct.SubRegionDisable = 0x00;
  MPU_InitStruct.TypeExtField = MPU_TEX_LEVEL0;
  MPU_InitStruct.AccessPermission = MPU_REGION_FULL_ACCESS;
  MPU_InitStruct.DisableExec = MPU_INSTRUCTION_ACCESS_ENABLE;
  MPU_InitStruct.IsShareable = MPU_ACCESS_NOT_SHAREABLE;
  MPU_InitStruct.IsCacheable = MPU_ACCESS_NOT_CACHEABLE;
  MPU_InitStruct.IsBufferable = MPU_ACCESS_NOT_BUFFERABLE;
  HAL_MPU_ConfigRegion(&MPU_InitStruct);

  /* 整个 D1 RAM 0x24000000: 非缓存
   * ⚠ 基地址必须按区域大小对齐, 0x24010000 不是512KB对齐会静默失败! */
  MPU_InitStruct.Number = MPU_REGION_NUMBER1;
  MPU_InitStruct.BaseAddress = 0x24000000;
  MPU_InitStruct.Size = MPU_REGION_SIZE_512KB;
  HAL_MPU_ConfigRegion(&MPU_InitStruct);

  HAL_MPU_Enable(MPU_PRIVILEGED_DEFAULT);
}

void HAL_TIM_PeriodElapsedCallback(TIM_HandleTypeDef *htim)
{
  if (htim->Instance == TIM6)
  {
    HAL_IncTick();
  }
}

void Error_Handler(void)
{
  __disable_irq();
  while (1)
  {
  }
}
